VERSION ""

NS_ :

BS_:

BU_: CCU

VAL_TABLE_ Rolling_Counter_0x403 15 "Invalid";
VAL_TABLE_ MHU_SET_TCS_OnOff 0 "OFF (keep sending for 2 seconds)" 1 "ON (keep sending for 2 seconds)" 2 "No action" 3 "Invalid";
VAL_TABLE_ MHU_SET_DrivingModeSwitch 3 "sport mode (should be hold during 1 second)" 2 "normal mode (should be hold during 1 second)" 1 "eco mode (should be hold during 1 second)" 0 "no change request";
VAL_TABLE_ MHU_SET_RegenLevel 3 "No action" 2 "High" 1 "Low" 0 "none";
VAL_TABLE_ MHU_VCU_CreepDisable_stt 0 "No request" 1 "Creep Disable request" 2 "Reserved" 3 "Invalid";
VAL_TABLE_ MHU_HVACTurnON 0 "No request" 1 "ON" 2 "Reserved" 3 "Invalid";
VAL_TABLE_ MHU_ChargeScheduleSet 0 "Disabled" 1 "Enabled" 2 "No Action" 3 "Reserved";
VAL_TABLE_ MHU_ChargingRequest 0 "Reserved" 1 "Request scheduled start charging" 2 "Request stop" 3 "No effect";
VAL_TABLE_ MHU_ValetMode_Activation 0 "Inactive" 1 "Active" 254 "Reserved" 255 "Invalid";
VAL_TABLE_ MHU_CCU_AC_Button 3 "Invalid" 1 "Press" 0 "Release";
VAL_TABLE_ MHU_REC_Button 3 "Invalid" 1 "Press" 0 "Release";
VAL_TABLE_ MHU_SetBlowMode 7 "Invalid" 6 "Reserve" 5 "Reserve" 4 "Foot and window" 3 "Foot" 2 "foot and face" 1 "face" 0 "Inactive";
VAL_TABLE_ MHU_BlowerLevelSetting 9 "level 8" 8 "level 7" 7 "level 6" 6 "level 5" 5 "level 4" 4 "level 3" 3 "level 2" 2 "level 1" 1 "OFF" 0 "Inactive";
VAL_TABLE_ MHU_SetDriverTemp 63 "Invalid" 16 "level 8" 15 "level 7" 14 "level 6" 13 "level 5" 12 "level 4" 11 "level 3" 10 "level 2" 9 "level 1" 8 "level 8" 7 "level 7" 6 "level 6" 5 "level 5" 4 "level 4" 3 "level 3" 2 "level 2" 1 "level 1" 0 "Inactive";
VAL_TABLE_ MHU_ACM_Reserved 3 "Invalid" 1 "Active" 0 "Inactive";
VAL_TABLE_ MHU_FrontDefrostReq_Reserved 3 "Invalid" 1 "Active" 0 "Inactive";
VAL_TABLE_ Rolling_Counter_0x422 15 "Invalid";
VAL_TABLE_ MHU_STAT_DateTimeFormat 3 "Signal invalid" 2 "Reserved" 1 "12H" 0 "24H";
VAL_TABLE_ MHU_DISPLAY_STATUS 0 "OFF" 1 "ON" 2 "Reserved" 3 "Invalid";
VAL_TABLE_ MHU_STAT_Language 31 "Signal invalid" 30 "Reserved" 29 "Reserved" 28 "Reserved" 27 "Reserved" 26 "Reserved" 25 "Reserved" 24 "Reserved" 23 "Reserved" 22 "Reserved" 21 "Reserved" 20 "Reserved" 19 "Reserved" 18 "Reserved" 17 "Reserved" 16 "Reserved" 15 "Reserved" 14 "Reserved" 13 "Reserved" 12 "Reserved" 11 "Reserved" 10 "Reserved" 9 "Reserved" 8 "Reserved" 7 "Reserved" 6 "Cambodia" 5 "Laos" 4 "Indonesian" 3 "Thai" 2 "Malay" 1 "English" 0 "Vietnamese";
VAL_TABLE_ REQ_ConsumerControlAudioVolumeCo 7 "signal invalid" 6 "Reserved" 5 "Reserved" 4 "Reserved" 3 "Reserved" 2 "Level 2" 1 "Level 1" 0 "No Reduction";
VAL_TABLE_ Rolling_Counter_0x432 15 "Invalid";
VAL_TABLE_ MHU_FOTA_State 0 "INIT" 1 "NORMAL" 2 "FOTA FLASHING" 3 "FOTA-SUSPENDED" 4 "FAIL-SAFE-ERROR" 5 "SHUTDOWN" 6 "REMOTE DIAGNOSTICS" 7 "Invalid";
VAL_TABLE_ XGW_FOTA_StateConfirm 0 "INIT" 1 "NORMAL" 2 "FOTA FLASHING" 3 "FOTA-SUSPENDED" 4 "FAIL-SAFE-ERROR" 5 "SHUTDOWN" 6 "REMOTE DIAGNOSTICS" 7 "Invalid";
VAL_TABLE_ IPC_Sec 63 "Invalid";
VAL_TABLE_ IPC_Min 63 "Invalid";
VAL_TABLE_ IPC_Hour 31 "Invalid";
VAL_TABLE_ IPC_Day 31 "Invalid";
VAL_TABLE_ IPC_Month 15 "Invalid";
VAL_TABLE_ IPC_Year 255 "Invalid";
VAL_TABLE_ IPC_SelfCheckStatus 1 "self-check finish" 0 "self-checking";
VAL_TABLE_ Rolling_Counter_0x20C 15 "Invalid";
VAL_TABLE_ IPC_ODO 1048575 "Invalid";
VAL_TABLE_ IPC_TripA 65535 "Invalid";
VAL_TABLE_ IPC_AverageSpeedTripA 4095 "Invalid";
VAL_TABLE_ IPC_AverageConsumptionTripA 1023 "Invalid";
VAL_TABLE_ IPC_ParkBrakeSts 3 "Invalid" 2 "Reserved" 1 "Applied" 0 "Released";
VAL_TABLE_ IPC_VehSpd 32767 "Invalid";
VAL_TABLE_ CCU_TemperatureGearSts 63 "Invalid" 16 "level 8" 15 "level 7" 14 "level 6" 13 "level 5" 12 "level 4" 11 "level 3" 10 "level 2" 9 "level 1" 8 "level 8" 7 "level 7" 6 "level 6" 5 "level 5" 4 "level 4" 3 "level 3" 2 "level 2" 1 "level 1" 0 "Inactive";
VAL_TABLE_ CCU_BlowMode_Sts 7 "Invalid" 6 "Reserve" 4 "Foot and window" 3 "Foot" 2 "Foot and Face" 1 "Face" 0 "OFF";
VAL_TABLE_ CCU_Circulation_Sts 1 "Internal circulation" 0 "Outer circulation";
VAL_TABLE_ CCU_AC_Req 3 "Invalid" 2 "Reserved" 1 "Requset" 0 "No requset";
VAL_TABLE_ CCU_AC_Sts 1 "ON" 0 "OFF";
VAL_TABLE_ CCU_BlowerLevelSts 8 "level 8" 7 "level 7" 6 "level 6" 5 "level 5" 4 "level 4" 3 "level 3" 2 "level 2" 1 "level 1" 0 "OFF";
VAL_TABLE_ CCU_FrontDefrostSts 1 "On" 0 "Off";
VAL_TABLE_ CCU_PTC_Req 3 "Invalid" 2 "Reserved" 1 "Requset" 0 "No requset";
VAL_TABLE_ CCU_PTC_Temperature 1023 "Invaild";
VAL_TABLE_ CCU_CompSpdMEAS_Comp 8191 "Invalid";
VAL_TABLE_ CCU_PollutionSts 1 "ON" 0 "OFF";
VAL_TABLE_ CCU_ExternalTemperature 255 "Invaild";
VAL_TABLE_ CCU_evaporator_Temperature 31 "Invalid";
VAL_TABLE_ CCU_ExternalTemperatureFailSts 1 "invalid" 0 "valid";
VAL_TABLE_ Rolling_Counter_0x85 15 "Invalid";
VAL_TABLE_ ACM_Crash_Sts 3 "Invalid Value" 2 "Invalid Value" 1 "Crash_Detected" 0 "No_Event";
VAL_TABLE_ ACM_Airbag_Deployment_Status 3 "Invalid Value" 2 "Invalid Value" 1 "Airbag_Deployment" 0 "No_Airbag_Deployment";
VAL_TABLE_ ACM_Crash_Intensity 7 "Invalid_Value" 6 "Invalid_Value" 5 "Invalid_Value" 4 "Invalid_Value" 3 "Crash_Intensity_3" 2 "Crash_Intensity_2" 1 "Crash_Intensity_1" 0 "No_Crash";
VAL_TABLE_ ACM_Front_Crash 3 "Invalid Value" 2 "Invalid Value" 1 "Front_Crash_Detected" 0 "No_Event";
VAL_TABLE_ ACM_DriverSide_Crash 3 "Invalid Value" 2 "Invalid Value" 1 "Driverside_Crash_Detected" 0 "No_Event";
VAL_TABLE_ ACM_PassSide_Crash 3 "Invalid Value" 2 "Invalid Value" 1 "PassSide_Crash_Detected" 0 "No_Event";
VAL_TABLE_ ACM_Rear_Crash 3 "Invalid Value" 2 "Invalid Value" 1 "Rear_Crash_Detected" 0 "No_Event";
VAL_TABLE_ ACM_Rollover_Crash 3 "Invalid Value" 2 "Invalid Value" 1 "Rollover_Crash_Detected" 0 "No_Event";
VAL_TABLE_ Rolling_Counter_0x10a 15 "Invalid";
VAL_TABLE_ BCM_LVTop_up 1 "start Top up" 0 "stop Top up";
VAL_TABLE_ Rolling_Counter_0x112 15 "Invalid";
VAL_TABLE_ STAT_Terminal 7 "Signal invalid" 6 "Reserved" 5 "Reserved" 4 "SW update OTA (Not used in VFe34)" 3 "Engine start (eMotor running)" 2 "ON (Driver Present)" 1 "ACC (Park)" 0 "OFF(Comfort Enable)";
VAL_TABLE_ STAT_CL30s_L_Reserved 3 "Signal invalid" 2 "Failure" 1 "ON" 0 "OFF";
VAL_TABLE_ Rolling_Counter_0x342 15 "Invalid";
VAL_TABLE_ ABS_LRWhlSpdRaw 32767 "Invalid";
VAL_TABLE_ ABS_LRWhlSpdRawValid 1 "Valid" 0 "Invalid";
VAL_TABLE_ ABS_RRWhlSpdRaw 32767 "Invalid";
VAL_TABLE_ ABS_RRWhlSpdRawValid 1 "Valid" 0 "Invalid";
VAL_TABLE_ ABS_VehSpd 32767 "Invalid";
VAL_TABLE_ ABS_VehSpdValid 1 "Valid" 0 "Invalid";
VAL_TABLE_ EAC_CompElecCurrV 0 "Valid" 1 "Invalid";
VAL_TABLE_ EAC_CompStat 0 "Normal Operation" 1 "Degraded Operation" 2 "Inoperative" 15 "Invalid";
VAL_TABLE_ EAC_CompElecPwrV 0 "Valid" 1 "Invalid";
VAL_TABLE_ EAC_CompSpdIncrReq 0 "False" 1 "True";
VAL_TABLE_ EAC_CompSpdV 0 "Valid" 1 "Invalid";
VAL_TABLE_ EAC_CompElecPwr 255 "Invaild";
VAL_TABLE_ EAC_CompSpd 16383 "Invaild";
VAL_TABLE_ EAC_CompElecCurr 255 "Invaild";
VAL_TABLE_ EAC_CompFltStat 0 "No Fault" 1 "Under Voltage" 2 "Over Voltage" 3 "Over Temperature" 4 "Input Control" 5 "Current Fault" 6 "Internal Fault" 8 "Motor slip protection" 9 "HVDC input voltage drop protection" 10 "Inside the controller 15V control power supply output undervoltage protection" 11 "Overcurrent frequency limitation and frequency reduction" 15 "Invalid";
VAL_TABLE_ VCU_PTC_RelaySts 1 "close" 0 "open";
VAL_TABLE_ VCU_EACEnbReq 1 "Enable" 0 "Disable";
VAL_TABLE_ VCU_EACAllowedPower 1023 "Invalid";
VAL_TABLE_ VCU_EAC_CompSpdReq 16383 "Invaild";
VAL_TABLE_ VCU_RegenLevel_Feed 3 "invalid" 2 "High" 1 "Low" 0 "none";
VAL_TABLE_ VCU_RBCSts 1 "active" 0 "incative";
VAL_TABLE_ VCU_RDCSts 1 "active" 0 "incative";
VAL_TABLE_ VCU_Veh_ERR 1 "Error" 0 "Normal";
VAL_TABLE_ VCU_DrvSys_ERR 1 "Error" 0 "Normal";
VAL_TABLE_ VCU_PackSys_ERR 1 "Error" 0 "Normal";
VAL_TABLE_ VCU_TBOX_Veh_STS_Reserved 3 "Other" 2 "Off" 1 "Start" 0 "Invalid";
VAL_TABLE_ VCU_VehChg_STS 3 "Charge fault" 2 "Charging complete" 1 "Charging in progress" 0 "Charging not in progress";
VAL_TABLE_ VCU_BatterVoltage_Reserved 255 "Invalid";
VAL_TABLE_ VCU_BatteryVoltErr_Reserved 1 "warning" 0 "no warning";
VAL_TABLE_ VCU_MotorCoolingCircuitErr_Reserved 1 "Error" 0 "Normal";
VAL_TABLE_ VCU_PackCoolingCircuitErr_Reserved 1 "Error" 0 "Normal";
VAL_TABLE_ VCU_VehicleHVStatus 3 "Reserved" 2 "ReadyToDrive" 1 "HV On" 0 "Not ready";
VAL_TABLE_ VCU_InstantPowerConsump 1023 "Invalid";
VAL_TABLE_ VCU_AveragePowerConsump 1023 "Invalid";
VAL_TABLE_ VCU_BrakePedalSts 3 "Invalid" 2 "Reserved" 1 "pressed" 0 "Not pressed";
VAL_TABLE_ VCU_IMMO_Sts 2 "failed " 1 "pass " 0 "init";
VAL_TABLE_ VCU_DCDCAllowedPower 511 "Invalid";
VAL_TABLE_ VCU_Shift_ERR 1 "Error" 0 "Normal";
VAL_TABLE_ VCU_VehicleDischargePower 127 "Invalid";
VAL_TABLE_ VCU_VehicleChargePower 127 "Invalid";
VAL_TABLE_ Rolling_Counter_0x215 15 "Invalid";
VAL_TABLE_ BMS_SOE 255 "Invalid";
VAL_TABLE_ BMS_HWCrash_Sts 1 "Crash " 0 "No Crash";
VAL_TABLE_ BMS_HVIL_STS 2 "short to ground" 1 "Open & short to battery" 0 "Closed";
VAL_TABLE_ BMS_IGN_Sts 1 "ON " 0 "OFF";
VAL_TABLE_ BMS_Sys_STS 8 "Invalid" 7 "Failure, unable to operate" 6 "BCU Sleep mode" 5 "Successful Power Down" 4 "Power Down process" 3 "Successful Power Down of HV" 2 "Successful High Voltage Power Up" 1 "Self-check passes, can be high-voltage" 0 "Initialization of power on, self-checking";
VAL_TABLE_ BMS_HVOnOff_STS 3 "Fail to HV on " 2 "HV On " 1 "Precharge " 0 "HV Off";
VAL_TABLE_ BMS_Balance_STS 1 "active " 0 "Inactive";
VAL_TABLE_ BMS_SocActual_EST 1023 "Invalid";
VAL_TABLE_ BMS_BatBalance_ERR 1 "normal " 0 "Error";
VAL_TABLE_ BMS_ISU_Status 3 "Level3(<100 Ohms/V)" 2 "Level2(<200 Ohms/V)" 1 "Level1 <500 Ohms/V ~ >200 Ohms/V" 0 "Normal (> 500 Ohms/V)";
VAL_TABLE_ BMS_ERR_LEV 7 "Battery locked -Reserved" 6 "Fault, needs Shutdown and Wakeup" 5 "Emergency off condition" 4 "Delayed power down with FTTI" 3 "Power down without FTTI" 2 "Limp Home" 1 " Warning (any warning in system)" 0 "No error";
VAL_TABLE_ BMS_SOH 255 "Invalid";
VAL_TABLE_ BMS_HV_Sts 4 "AC Charge" 3 "Super Fast Charge" 2 "HV ON" 1 "Precharge" 0 "HV Off";
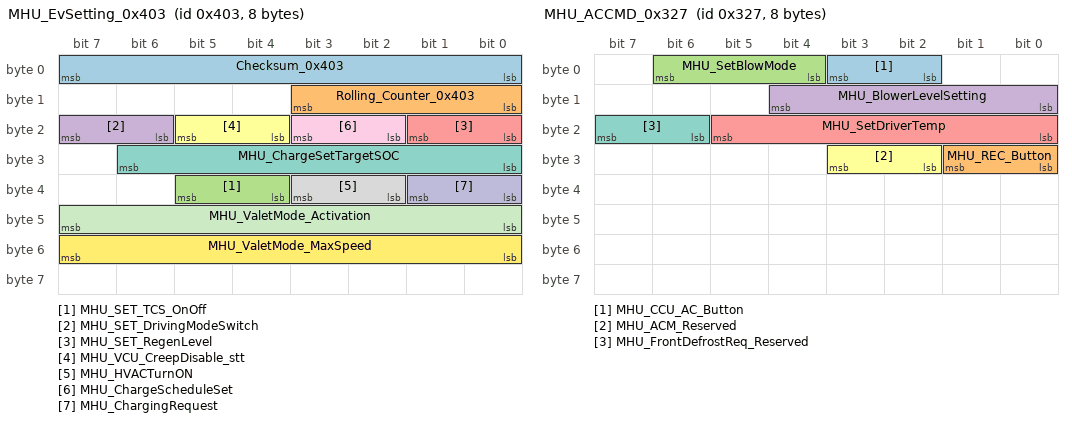
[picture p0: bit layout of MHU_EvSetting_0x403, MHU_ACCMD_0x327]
BO_ 1027 MHU_EvSetting_0x403: 8 Vector__XXX
 SG_ Checksum_0x403 : 7|8@0+ (1,0) [0|255] "" Vector__XXX
 SG_ Rolling_Counter_0x403 : 11|4@0+ (1,0) [0|15] "" Vector__XXX
 SG_ MHU_SET_TCS_OnOff : 37|2@0+ (1,0) [0|3] "" Vector__XXX
 SG_ MHU_SET_DrivingModeSwitch : 23|2@0+ (1,0) [0|3] "" Vector__XXX
 SG_ MHU_SET_RegenLevel : 17|2@0+ (1,0) [0|3] "" Vector__XXX
 SG_ MHU_VCU_CreepDisable_stt : 21|2@0+ (1,0) [0|3] "" Vector__XXX
 SG_ MHU_ChargeSetTargetSOC : 30|7@0+ (1,0) [10|100] "Percentage" Vector__XXX
 SG_ MHU_HVACTurnON : 35|2@0+ (1,0) [0|3] "" CCU
 SG_ MHU_ChargeScheduleSet : 19|2@0+ (1,0) [0|3] "" Vector__XXX
 SG_ MHU_ChargingRequest : 33|2@0+ (1,0) [0|3] "" Vector__XXX
 SG_ MHU_ValetMode_Activation : 47|8@0+ (1,0) [0|254] "" Vector__XXX
 SG_ MHU_ValetMode_MaxSpeed : 55|8@0+ (1,0) [0|254] "kph" Vector__XXX
BO_ 807 MHU_ACCMD_0x327: 8 Vector__XXX
 SG_ MHU_CCU_AC_Button : 3|2@0+ (1,0) [0|3] "" CCU
 SG_ MHU_REC_Button : 25|2@0+ (1,0) [0|3] "" CCU
 SG_ MHU_SetBlowMode : 6|3@0+ (1,0) [0|7] "" CCU
 SG_ MHU_BlowerLevelSetting : 12|5@0+ (1,0) [0|9] "" CCU
 SG_ MHU_SetDriverTemp : 21|6@0+ (1,0) [0|63] "" CCU
 SG_ MHU_ACM_Reserved : 27|2@0+ (1,0) [0|3] "" CCU
 SG_ MHU_FrontDefrostReq_Reserved : 23|2@0+ (1,0) [0|3] "" CCU
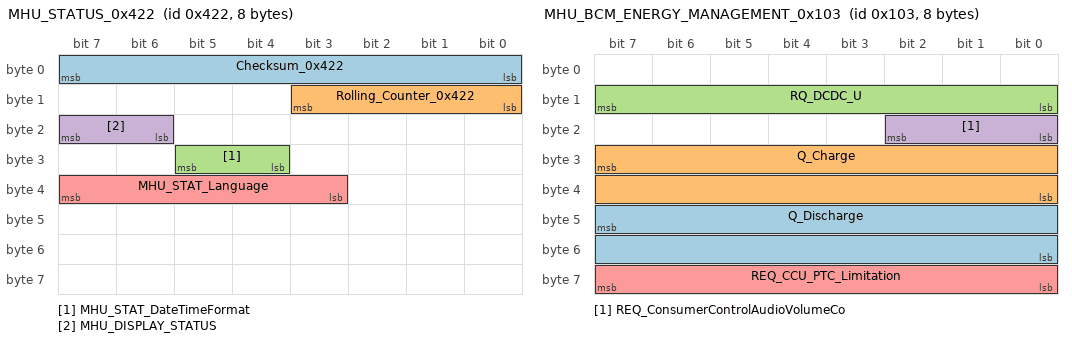
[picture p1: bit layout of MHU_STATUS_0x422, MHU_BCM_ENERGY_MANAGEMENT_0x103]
BO_ 1058 MHU_STATUS_0x422: 8 Vector__XXX
 SG_ Checksum_0x422 : 7|8@0+ (1,0) [0|255] "" Vector__XXX
 SG_ Rolling_Counter_0x422 : 11|4@0+ (1,0) [0|15] "" Vector__XXX
 SG_ MHU_STAT_DateTimeFormat : 29|2@0+ (1,0) [0|3] "" Vector__XXX
 SG_ MHU_DISPLAY_STATUS : 23|2@0+ (1,0) [0|3] "" CCU
 SG_ MHU_STAT_Language : 39|5@0+ (1,0) [0|31] "" Vector__XXX
BO_ 259 MHU_BCM_ENERGY_MANAGEMENT_0x103: 8 Vector__XXX
 SG_ Q_Discharge : 47|16@0+ (0.125,0) [0|8191.75] "Ah" CCU
 SG_ Q_Charge : 31|16@0+ (0.125,0) [0|8191.75] "Ah" CCU
 SG_ RQ_DCDC_U : 15|8@0+ (0.1,0) [0|25.2] "Vol" CCU
 SG_ REQ_ConsumerControlAudioVolumeCo : 18|3@0+ (1,0) [0|7] "" CCU
 SG_ REQ_CCU_PTC_Limitation : 63|8@0+ (1,0) [0|100] "percent" CCU
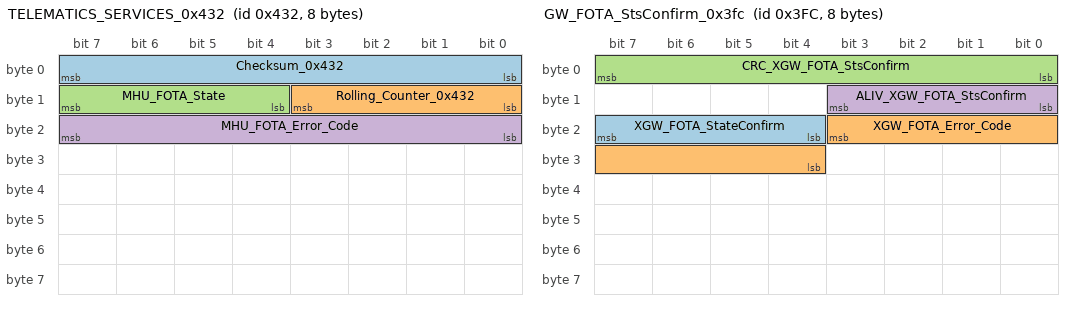
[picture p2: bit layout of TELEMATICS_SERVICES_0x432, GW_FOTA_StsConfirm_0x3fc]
BO_ 1074 TELEMATICS_SERVICES_0x432: 8 Vector__XXX
 SG_ Checksum_0x432 : 7|8@0+ (1,0) [0|255] "" CCU
 SG_ Rolling_Counter_0x432 : 11|4@0+ (1,0) [0|14] "" CCU
 SG_ MHU_FOTA_State : 15|4@0+ (1,0) [0|14] "" CCU
 SG_ MHU_FOTA_Error_Code : 23|8@0+ (1,0) [0|255] "" CCU
BO_ 1020 GW_FOTA_StsConfirm_0x3fc: 8 Vector__XXX
 SG_ XGW_FOTA_StateConfirm : 23|4@0+ (1,0) [0|14] "" CCU
 SG_ XGW_FOTA_Error_Code : 19|8@0+ (1,0) [0|255] "" Vector__XXX
 SG_ CRC_XGW_FOTA_StsConfirm : 7|8@0+ (1,0) [0|255] "" Vector__XXX
 SG_ ALIV_XGW_FOTA_StsConfirm : 11|4@0+ (1,0) [0|14] "" Vector__XXX
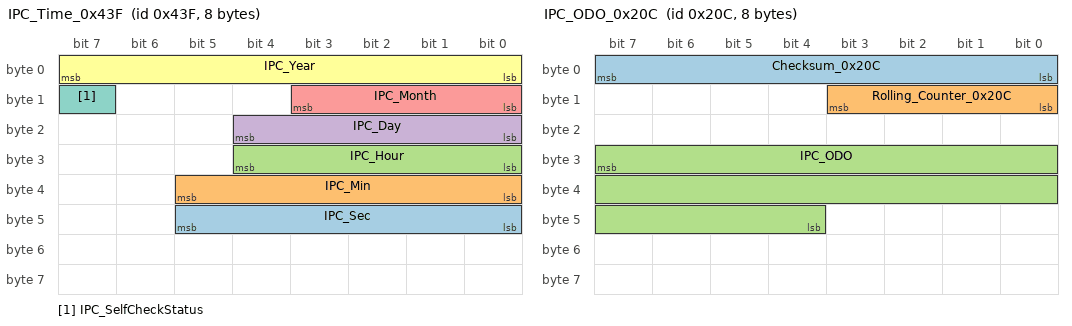
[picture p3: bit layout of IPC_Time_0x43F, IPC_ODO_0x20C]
BO_ 1087 IPC_Time_0x43F: 8 Vector__XXX
 SG_ IPC_Sec : 45|6@0+ (1,0) [0|59] "second" CCU
 SG_ IPC_Min : 37|6@0+ (1,0) [0|59] "min" CCU
 SG_ IPC_Hour : 28|5@0+ (1,0) [0|23] "hour" CCU
 SG_ IPC_Day : 20|5@0+ (1,0) [1|31] "" CCU
 SG_ IPC_Month : 11|4@0+ (1,0) [1|12] "" CCU
 SG_ IPC_Year : 7|8@0+ (1,2000) [2000|2255] "" CCU
 SG_ IPC_SelfCheckStatus : 15|1@0+ (1,0) [0|1] "" CCU
BO_ 524 IPC_ODO_0x20C: 8 Vector__XXX
 SG_ Checksum_0x20C : 7|8@0+ (1,0) [0|255] "" Vector__XXX
 SG_ Rolling_Counter_0x20C : 11|4@0+ (1,0) [0|15] "" Vector__XXX
 SG_ IPC_ODO : 31|20@0+ (1,0) [0|999999] "km" CCU
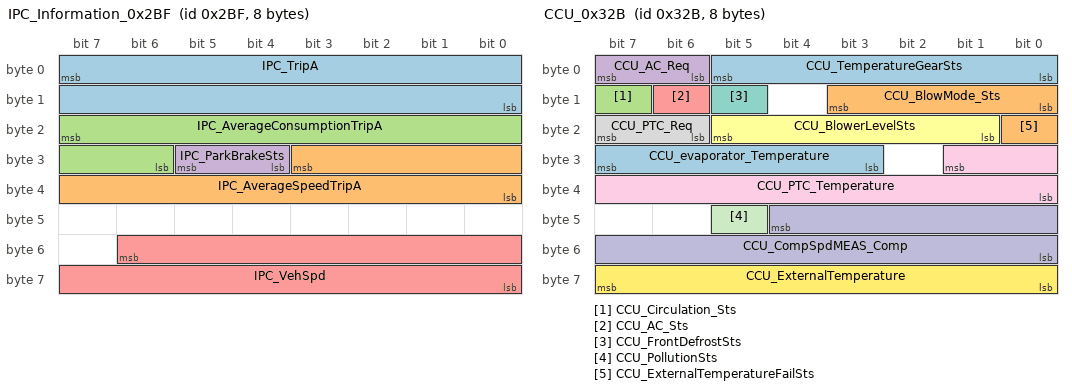
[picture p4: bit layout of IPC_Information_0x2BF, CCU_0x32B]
BO_ 703 IPC_Information_0x2BF: 8 Vector__XXX
 SG_ IPC_TripA : 7|16@0+ (0.1,0) [0|999.9] "km" Vector__XXX
 SG_ IPC_AverageSpeedTripA : 27|12@0+ (0.0625,0) [0|250] "km/h" Vector__XXX
 SG_ IPC_AverageConsumptionTripA : 23|10@0+ (0.1,0) [0|100] "kwh/100km" Vector__XXX
 SG_ IPC_ParkBrakeSts : 29|2@0+ (1,0) [0|3] "" Vector__XXX
 SG_ IPC_VehSpd : 54|15@0+ (0.01,0) [0|327.66] "kph" CCU
BO_ 811 CCU_0x32B: 8 CCU
 SG_ CCU_TemperatureGearSts : 5|6@0+ (1,0) [0|63] "" Vector__XXX
 SG_ CCU_BlowMode_Sts : 11|4@0+ (1,0) [0|15] "" Vector__XXX
 SG_ CCU_Circulation_Sts : 15|1@0+ (1,0) [0|1] "" Vector__XXX
 SG_ CCU_AC_Req : 7|2@0+ (1,0) [0|3] "" Vector__XXX
 SG_ CCU_AC_Sts : 14|1@0+ (1,0) [0|1] "" Vector__XXX
 SG_ CCU_BlowerLevelSts : 21|5@0+ (1,0) [0|9] "" Vector__XXX
 SG_ CCU_FrontDefrostSts : 13|1@0+ (1,0) [0|1] "" Vector__XXX
 SG_ CCU_PTC_Req : 23|2@0+ (1,0) [0|3] "" Vector__XXX
 SG_ CCU_PTC_Temperature : 25|10@0+ (0.1,0) [0|100] "°C" Vector__XXX
 SG_ CCU_CompSpdMEAS_Comp : 44|13@0+ (1,0) [0|8191] "rpm" Vector__XXX
 SG_ CCU_PollutionSts : 45|1@0+ (1,0) [0|1] "" Vector__XXX
 SG_ CCU_ExternalTemperature : 63|8@0+ (0.5,-40) [-40|87] "°C" Vector__XXX
 SG_ CCU_evaporator_Temperature : 31|5@0+ (1,-10) [-10|20] "°C" Vector__XXX
 SG_ CCU_ExternalTemperatureFailSts : 16|1@0+ (1,0) [0|1] "" Vector__XXX
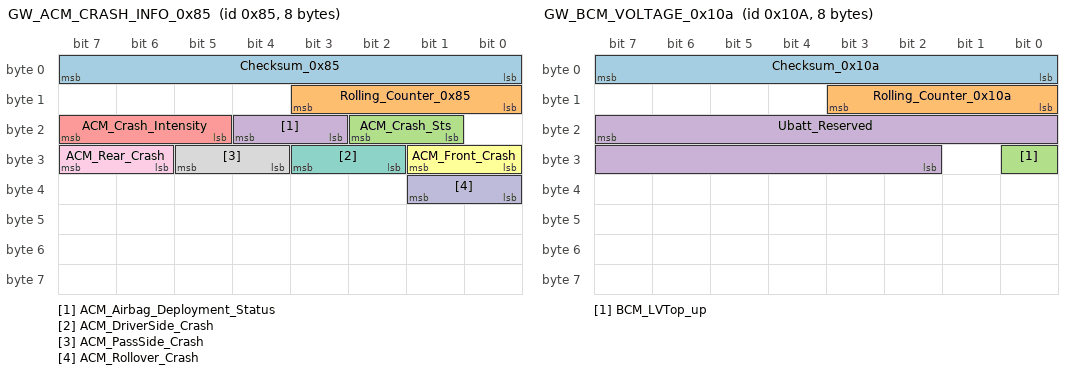
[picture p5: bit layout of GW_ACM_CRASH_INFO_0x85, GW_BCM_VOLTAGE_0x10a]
BO_ 133 GW_ACM_CRASH_INFO_0x85: 8 Vector__XXX
 SG_ Checksum_0x85 : 7|8@0+ (1,0) [0|255] "" CCU
 SG_ Rolling_Counter_0x85 : 11|4@0+ (1,0) [0|15] "" CCU
 SG_ ACM_Crash_Sts : 18|2@0+ (1,0) [0|3] "" CCU
 SG_ ACM_Airbag_Deployment_Status : 20|2@0+ (1,0) [0|3] "" Vector__XXX
 SG_ ACM_Crash_Intensity : 23|3@0+ (1,0) [0|7] "" Vector__XXX
 SG_ ACM_Front_Crash : 25|2@0+ (1,0) [0|3] "" Vector__XXX
 SG_ ACM_DriverSide_Crash : 27|2@0+ (1,0) [0|3] "" Vector__XXX
 SG_ ACM_PassSide_Crash : 29|2@0+ (1,0) [0|3] "" Vector__XXX
 SG_ ACM_Rear_Crash : 31|2@0+ (1,0) [0|3] "" Vector__XXX
 SG_ ACM_Rollover_Crash : 33|2@0+ (1,0) [0|3] "" Vector__XXX
BO_ 266 GW_BCM_VOLTAGE_0x10a: 8 Vector__XXX
 SG_ Checksum_0x10a : 7|8@0+ (1,0) [0|255] "" CCU
 SG_ Rolling_Counter_0x10a : 11|4@0+ (1,0) [0|15] "" CCU
 SG_ BCM_LVTop_up : 24|1@0+ (1,0) [0|1] "" Vector__XXX
 SG_ Ubatt_Reserved : 23|14@0+ (0.001,3) [3|18] "V" CCU
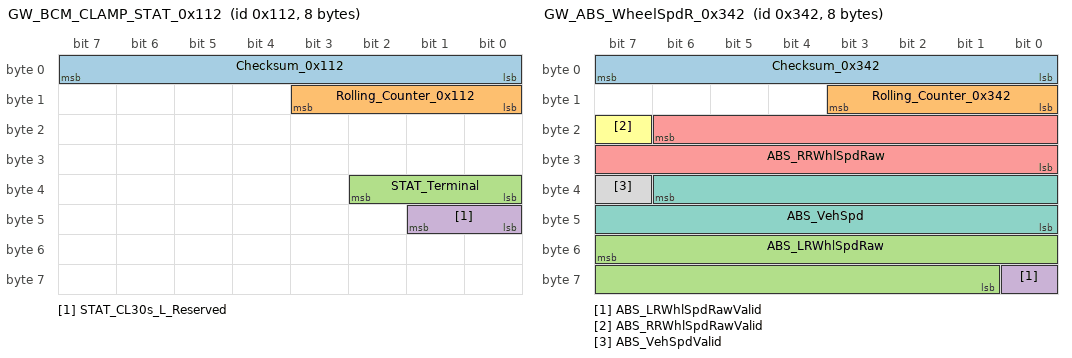
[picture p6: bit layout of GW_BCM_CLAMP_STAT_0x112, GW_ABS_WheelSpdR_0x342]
BO_ 274 GW_BCM_CLAMP_STAT_0x112: 8 Vector__XXX
 SG_ Checksum_0x112 : 7|8@0+ (1,0) [0|255] "" CCU
 SG_ Rolling_Counter_0x112 : 11|4@0+ (1,0) [0|15] "" CCU
 SG_ STAT_Terminal : 34|3@0+ (1,0) [0|7] "Bit" CCU
 SG_ STAT_CL30s_L_Reserved : 41|2@0+ (1,0) [0|3] "Bit" Vector__XXX
BO_ 834 GW_ABS_WheelSpdR_0x342: 8 Vector__XXX
 SG_ Checksum_0x342 : 7|8@0+ (1,0) [0|255] "" CCU
 SG_ Rolling_Counter_0x342 : 11|4@0+ (1,0) [0|15] "" CCU
 SG_ ABS_LRWhlSpdRaw : 55|15@0+ (0.01,0) [0|327.66] "kph" Vector__XXX
 SG_ ABS_LRWhlSpdRawValid : 56|1@0+ (1,0) [0|1] "" Vector__XXX
 SG_ ABS_RRWhlSpdRaw : 22|15@0+ (0.01,0) [0|327.66] "kph" Vector__XXX
 SG_ ABS_RRWhlSpdRawValid : 23|1@0+ (1,0) [0|1] "" Vector__XXX
 SG_ ABS_VehSpd : 38|15@0+ (0.01,0) [0|327.66] "kph" CCU
 SG_ ABS_VehSpdValid : 39|1@0+ (1,0) [0|1] "" CCU
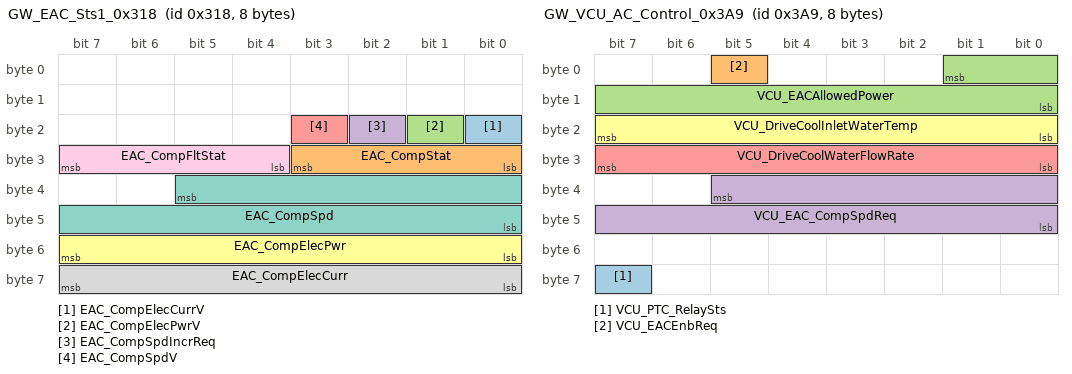
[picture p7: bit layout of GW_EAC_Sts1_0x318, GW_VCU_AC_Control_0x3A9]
BO_ 792 GW_EAC_Sts1_0x318: 8 Vector__XXX
 SG_ EAC_CompElecCurrV : 16|1@0+ (1,0) [0|1] "" Vector__XXX
 SG_ EAC_CompStat : 27|4@0+ (1,0) [0|15] "" CCU
 SG_ EAC_CompElecPwrV : 17|1@0+ (1,0) [0|1] "" Vector__XXX
 SG_ EAC_CompSpdIncrReq : 18|1@0+ (1,0) [0|1] "" Vector__XXX
 SG_ EAC_CompSpdV : 19|1@0+ (1,0) [0|1] "" CCU
 SG_ EAC_CompElecPwr : 55|8@0+ (40,0) [0|10200] "W" CCU
 SG_ EAC_CompSpd : 37|14@0+ (1,0) [0|16383] "rpm" CCU
 SG_ EAC_CompElecCurr : 63|8@0+ (0.2,0) [0|51] "A" Vector__XXX
 SG_ EAC_CompFltStat : 31|4@0+ (1,0) [0|15] "" CCU
BO_ 937 GW_VCU_AC_Control_0x3A9: 8 Vector__XXX
 SG_ VCU_PTC_RelaySts : 63|1@0+ (1,0) [0|1] "" CCU
 SG_ VCU_EACEnbReq : 5|1@0+ (1,0) [0|1] "" Vector__XXX
 SG_ VCU_EACAllowedPower : 1|10@0+ (0.1,0) [0|100] "KW" Vector__XXX
 SG_ VCU_EAC_CompSpdReq : 37|14@0+ (1,0) [0|16383] "rpm" Vector__XXX
 SG_ VCU_DriveCoolWaterFlowRate : 31|8@0+ (0.1,0) [0|25.4] "L/min" Vector__XXX
 SG_ VCU_DriveCoolInletWaterTemp : 23|8@0+ (1,-40) [-40|215] "degree" Vector__XXX
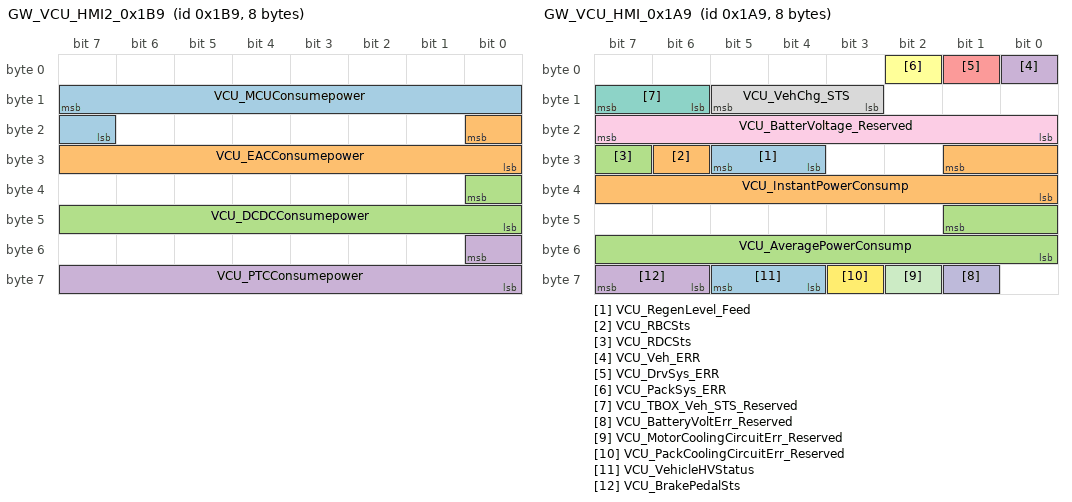
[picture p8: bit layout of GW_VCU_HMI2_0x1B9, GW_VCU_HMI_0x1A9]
BO_ 441 GW_VCU_HMI2_0x1B9: 8 Vector__XXX
 SG_ VCU_MCUConsumepower : 15|9@0+ (0.1,0) [0|50] "kw/h" Vector__XXX
 SG_ VCU_EACConsumepower : 16|9@0+ (0.1,0) [0|50] "kw/h" Vector__XXX
 SG_ VCU_DCDCConsumepower : 32|9@0+ (0.1,0) [0|50] "kw/h" Vector__XXX
 SG_ VCU_PTCConsumepower : 48|9@0+ (0.1,0) [0|50] "kw/h" Vector__XXX
BO_ 425 GW_VCU_HMI_0x1A9: 8 Vector__XXX
 SG_ VCU_RegenLevel_Feed : 29|2@0+ (1,0) [0|3] "" Vector__XXX
 SG_ VCU_RBCSts : 30|1@0+ (1,0) [0|1] "" Vector__XXX
 SG_ VCU_RDCSts : 31|1@0+ (1,0) [0|1] "" Vector__XXX
 SG_ VCU_Veh_ERR : 0|1@0+ (1,0) [0|1] "" Vector__XXX
 SG_ VCU_DrvSys_ERR : 1|1@0+ (1,0) [0|1] "" Vector__XXX
 SG_ VCU_PackSys_ERR : 2|1@0+ (1,0) [0|1] "" Vector__XXX
 SG_ VCU_TBOX_Veh_STS_Reserved : 15|2@0+ (1,0) [0|3] "" Vector__XXX
 SG_ VCU_VehChg_STS : 13|3@0+ (1,0) [0|7] "" Vector__XXX
 SG_ VCU_BatterVoltage_Reserved : 23|8@0+ (0.07,0) [0|17.85] "V" Vector__XXX
 SG_ VCU_BatteryVoltErr_Reserved : 57|1@0+ (1,0) [0|1] "" Vector__XXX
 SG_ VCU_MotorCoolingCircuitErr_Reserved : 58|1@0+ (1,0) [0|1] "" Vector__XXX
 SG_ VCU_PackCoolingCircuitErr_Reserved : 59|1@0+ (1,0) [0|1] "" Vector__XXX
 SG_ VCU_VehicleHVStatus : 61|2@0+ (1,0) [0|3] "" CCU
 SG_ VCU_InstantPowerConsump : 25|10@0+ (0.1,0) [0|100] "kwh/100km" Vector__XXX
 SG_ VCU_AveragePowerConsump : 41|10@0+ (0.1,0) [0|100] "kwh/100km" Vector__XXX
 SG_ VCU_BrakePedalSts : 63|2@0+ (1,0) [0|3] "" Vector__XXX
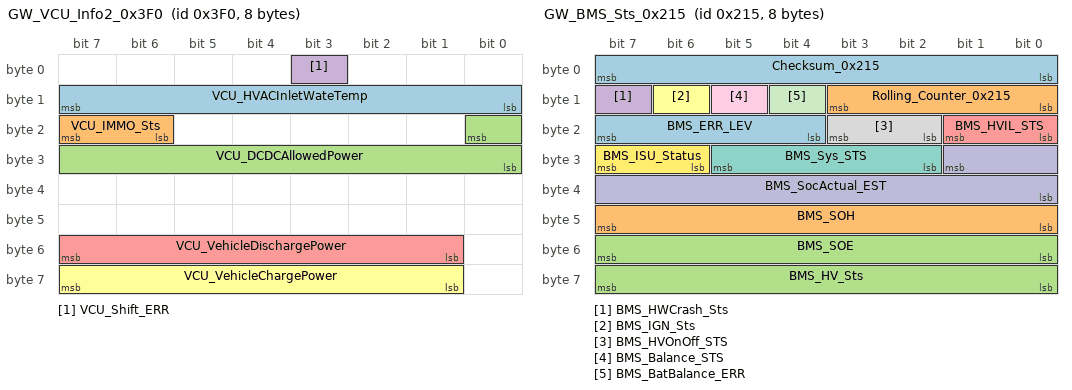
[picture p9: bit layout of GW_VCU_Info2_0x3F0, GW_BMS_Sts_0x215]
BO_ 1008 GW_VCU_Info2_0x3F0: 8 Vector__XXX
 SG_ VCU_HVACInletWateTemp : 15|8@0+ (1,-40) [-40|215] "degree" CCU
 SG_ VCU_IMMO_Sts : 23|2@0+ (1,0) [0|2] "" Vector__XXX
 SG_ VCU_DCDCAllowedPower : 16|9@0+ (0.1,0) [0|50] "KW" Vector__XXX
 SG_ VCU_Shift_ERR : 3|1@0+ (1,0) [0|1] "" Vector__XXX
 SG_ VCU_VehicleDischargePower : 55|7@0+ (1,0) [0|100] "%" Vector__XXX
 SG_ VCU_VehicleChargePower : 63|7@0+ (1,0) [0|100] "%" Vector__XXX
BO_ 533 GW_BMS_Sts_0x215: 8 Vector__XXX
 SG_ Checksum_0x215 : 7|8@0+ (1,0) [0|255] "" CCU
 SG_ Rolling_Counter_0x215 : 11|4@0+ (1,0) [0|15] "" CCU
 SG_ BMS_SOE : 55|8@0+ (0.5,0) [0|100] "%" Vector__XXX
 SG_ BMS_HWCrash_Sts : 15|1@0+ (1,0) [0|1] "" Vector__XXX
 SG_ BMS_HVIL_STS : 17|2@0+ (1,0) [0|3] "" Vector__XXX
 SG_ BMS_IGN_Sts : 14|1@0+ (1,0) [0|1] "" Vector__XXX
 SG_ BMS_Sys_STS : 29|4@0+ (1,0) [0|15] "" Vector__XXX
 SG_ BMS_HVOnOff_STS : 19|2@0+ (1,0) [0|3] "" CCU
 SG_ BMS_Balance_STS : 13|1@0+ (1,0) [0|1] "" Vector__XXX
 SG_ BMS_SocActual_EST : 25|10@0+ (0.1,0) [0|100] "percent" Vector__XXX
 SG_ BMS_BatBalance_ERR : 12|1@0+ (1,0) [0|1] "" Vector__XXX
 SG_ BMS_ISU_Status : 31|2@0+ (1,0) [0|3] "" Vector__XXX
 SG_ BMS_ERR_LEV : 23|4@0+ (1,0) [0|15] "" Vector__XXX
 SG_ BMS_SOH : 47|8@0+ (0.5,0) [0|100] "%" Vector__XXX
 SG_ BMS_HV_Sts : 63|8@0+ (1,0) [0|255] "" Vector__XXX
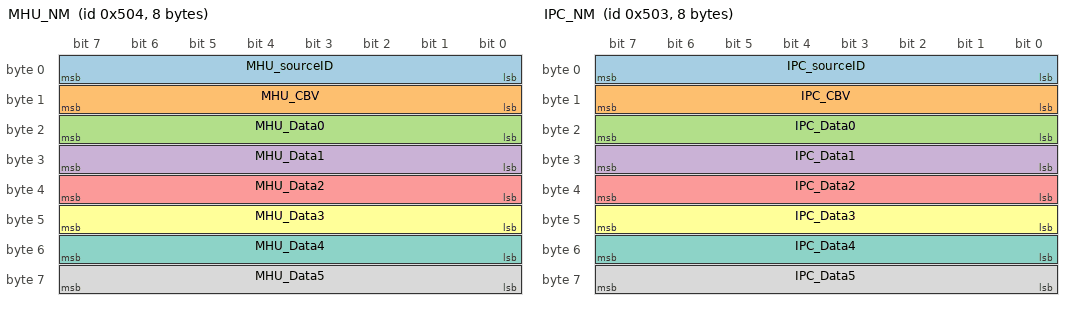
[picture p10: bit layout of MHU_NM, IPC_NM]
BO_ 1284 MHU_NM: 8 Vector__XXX
 SG_ MHU_sourceID : 7|8@0+ (1,0) [0|255] "" CCU
 SG_ MHU_CBV : 15|8@0+ (1,0) [0|255] "" CCU
 SG_ MHU_Data0 : 23|8@0+ (1,0) [0|255] "" CCU
 SG_ MHU_Data1 : 31|8@0+ (1,0) [0|255] "" CCU
 SG_ MHU_Data2 : 39|8@0+ (1,0) [0|255] "" CCU
 SG_ MHU_Data3 : 47|8@0+ (1,0) [0|255] "" CCU
 SG_ MHU_Data4 : 55|8@0+ (1,0) [0|255] "" CCU
 SG_ MHU_Data5 : 63|8@0+ (1,0) [0|255] "" CCU
BO_ 1283 IPC_NM: 8 Vector__XXX
 SG_ IPC_sourceID : 7|8@0+ (1,0) [0|255] "" CCU
 SG_ IPC_CBV : 15|8@0+ (1,0) [0|255] "" CCU
 SG_ IPC_Data0 : 23|8@0+ (1,0) [0|255] "" CCU
 SG_ IPC_Data1 : 31|8@0+ (1,0) [0|255] "" CCU
 SG_ IPC_Data2 : 39|8@0+ (1,0) [0|255] "" CCU
 SG_ IPC_Data3 : 47|8@0+ (1,0) [0|255] "" CCU
 SG_ IPC_Data4 : 55|8@0+ (1,0) [0|255] "" CCU
 SG_ IPC_Data5 : 63|8@0+ (1,0) [0|255] "" CCU
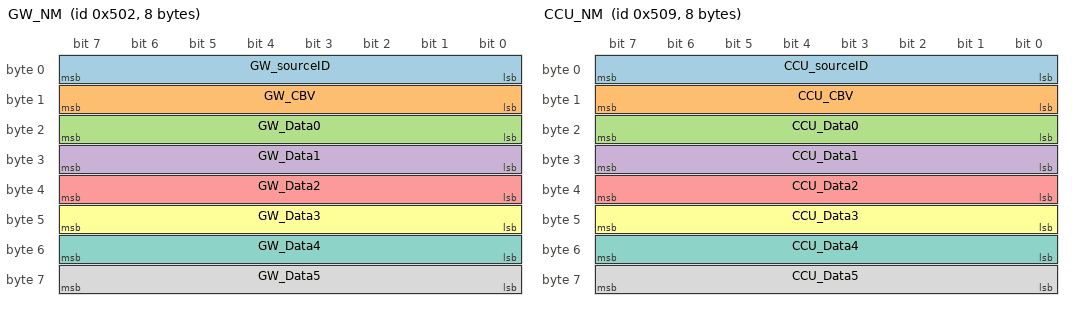
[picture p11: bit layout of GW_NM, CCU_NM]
BO_ 1282 GW_NM: 8 Vector__XXX
 SG_ GW_sourceID : 7|8@0+ (1,0) [0|255] "" CCU
 SG_ GW_CBV : 15|8@0+ (1,0) [0|255] "" CCU
 SG_ GW_Data0 : 23|8@0+ (1,0) [0|255] "" CCU
 SG_ GW_Data1 : 31|8@0+ (1,0) [0|255] "" CCU
 SG_ GW_Data2 : 39|8@0+ (1,0) [0|255] "" CCU
 SG_ GW_Data3 : 47|8@0+ (1,0) [0|255] "" CCU
 SG_ GW_Data4 : 55|8@0+ (1,0) [0|255] "" CCU
 SG_ GW_Data5 : 63|8@0+ (1,0) [0|255] "" CCU
BO_ 1289 CCU_NM: 8 CCU
 SG_ CCU_sourceID : 7|8@0+ (1,0) [0|255] "" Vector__XXX
 SG_ CCU_CBV : 15|8@0+ (1,0) [0|255] "" Vector__XXX
 SG_ CCU_Data0 : 23|8@0+ (1,0) [0|255] "" Vector__XXX
 SG_ CCU_Data1 : 31|8@0+ (1,0) [0|255] "" Vector__XXX
 SG_ CCU_Data2 : 39|8@0+ (1,0) [0|255] "" Vector__XXX
 SG_ CCU_Data3 : 47|8@0+ (1,0) [0|255] "" Vector__XXX
 SG_ CCU_Data4 : 55|8@0+ (1,0) [0|255] "" Vector__XXX
 SG_ CCU_Data5 : 63|8@0+ (1,0) [0|255] "" Vector__XXX
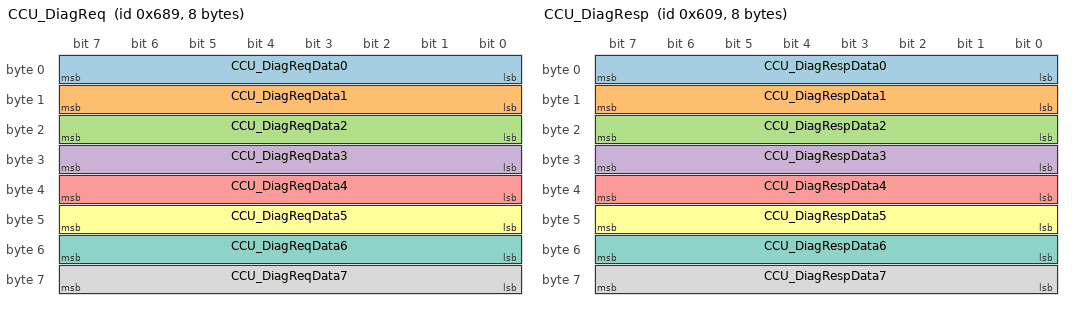
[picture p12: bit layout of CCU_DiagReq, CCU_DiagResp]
BO_ 1673 CCU_DiagReq: 8 Vector__XXX
 SG_ CCU_DiagReqData0 : 7|8@0+ (1,0) [0|255] "" CCU
 SG_ CCU_DiagReqData1 : 15|8@0+ (1,0) [0|255] "" CCU
 SG_ CCU_DiagReqData2 : 23|8@0+ (1,0) [0|255] "" CCU
 SG_ CCU_DiagReqData3 : 31|8@0+ (1,0) [0|255] "" CCU
 SG_ CCU_DiagReqData4 : 39|8@0+ (1,0) [0|255] "" CCU
 SG_ CCU_DiagReqData5 : 47|8@0+ (1,0) [0|255] "" CCU
 SG_ CCU_DiagReqData6 : 55|8@0+ (1,0) [0|255] "" CCU
 SG_ CCU_DiagReqData7 : 63|8@0+ (1,0) [0|255] "" CCU
BO_ 1545 CCU_DiagResp: 8 CCU
 SG_ CCU_DiagRespData0 : 7|8@0+ (1,0) [0|255] "" Vector__XXX
 SG_ CCU_DiagRespData1 : 15|8@0+ (1,0) [0|255] "" Vector__XXX
 SG_ CCU_DiagRespData2 : 23|8@0+ (1,0) [0|255] "" Vector__XXX
 SG_ CCU_DiagRespData3 : 31|8@0+ (1,0) [0|255] "" Vector__XXX
 SG_ CCU_DiagRespData4 : 39|8@0+ (1,0) [0|255] "" Vector__XXX
 SG_ CCU_DiagRespData5 : 47|8@0+ (1,0) [0|255] "" Vector__XXX
 SG_ CCU_DiagRespData6 : 55|8@0+ (1,0) [0|255] "" Vector__XXX
 SG_ CCU_DiagRespData7 : 63|8@0+ (1,0) [0|255] "" Vector__XXX
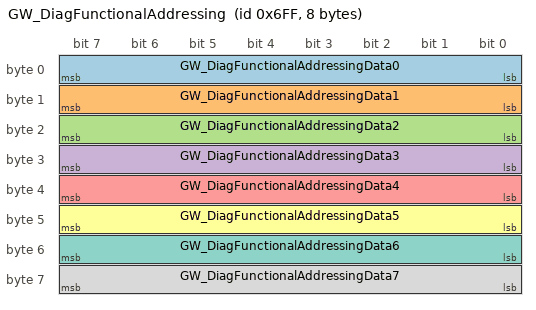
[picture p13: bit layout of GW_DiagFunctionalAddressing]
BO_ 1791 GW_DiagFunctionalAddressing: 8 Vector__XXX
 SG_ GW_DiagFunctionalAddressingData0 : 7|8@0+ (1,0) [0|255] "" CCU
 SG_ GW_DiagFunctionalAddressingData1 : 15|8@0+ (1,0) [0|255] "" CCU
 SG_ GW_DiagFunctionalAddressingData2 : 23|8@0+ (1,0) [0|255] "" CCU
 SG_ GW_DiagFunctionalAddressingData3 : 31|8@0+ (1,0) [0|255] "" CCU
 SG_ GW_DiagFunctionalAddressingData4 : 39|8@0+ (1,0) [0|255] "" CCU
 SG_ GW_DiagFunctionalAddressingData5 : 47|8@0+ (1,0) [0|255] "" CCU
 SG_ GW_DiagFunctionalAddressingData6 : 55|8@0+ (1,0) [0|255] "" CCU
 SG_ GW_DiagFunctionalAddressingData7 : 63|8@0+ (1,0) [0|255] "" CCU
CM_ SG_ 1027 Checksum_0x403 "Checksum";
CM_ SG_ 1027 Rolling_Counter_0x403 "Rolling_Counter";
CM_ SG_ 1027 MHU_SET_TCS_OnOff "Change TCS mode ON/OFF";
CM_ SG_ 1027 MHU_SET_DrivingModeSwitch "Change vehicle driving mode";
CM_ SG_ 1027 MHU_SET_RegenLevel "Set power regenerative level";
CM_ SG_ 1027 MHU_VCU_CreepDisable_stt "Request for VCU to disable creep function";
CM_ SG_ 1027 MHU_ChargeSetTargetSOC "Request for VCU to set target HV SOC";
CM_ SG_ 1027 MHU_HVACTurnON "Turning ON HVAC remotely";
CM_ SG_ 1027 MHU_ChargeScheduleSet "Request for VCU to enable/disable Charging Scheduling";
CM_ SG_ 1027 MHU_ChargingRequest "Request for VCU to ON/OFF Charging when schedule is reached";
CM_ SG_ 1027 MHU_ValetMode_Activation "Activate Valet mode from MHU";
CM_ SG_ 1027 MHU_ValetMode_MaxSpeed "Setting of maximum allowable in valet mode";
CM_ SG_ 807 MHU_CCU_AC_Button "Compressor Request Button";
CM_ SG_ 807 MHU_REC_Button "Loop mode Button";
CM_ SG_ 807 MHU_SetBlowMode "Set AC Mode";
CM_ SG_ 807 MHU_BlowerLevelSetting "Blower Level Setting";
CM_ SG_ 807 MHU_SetDriverTemp "Set Driver AC Temp level";
CM_ SG_ 807 MHU_ACM_Reserved "Air Conditioning PTC Switches(for new energy models with PTC only)";
CM_ SG_ 807 MHU_FrontDefrostReq_Reserved "Front Defrost Req";
CM_ SG_ 1058 Checksum_0x422 "Checksum";
CM_ SG_ 1058 Rolling_Counter_0x422 "Rolling_Counter";
CM_ SG_ 1058 MHU_STAT_DateTimeFormat "Indicate current date time format (12H and 24H)";
CM_ SG_ 1058 MHU_DISPLAY_STATUS "MHU for screen status";
CM_ SG_ 1058 MHU_STAT_Language "Indicate current Language";
CM_ SG_ 259 Q_Discharge "Negative";
CM_ SG_ 259 Q_Charge "Positive";
CM_ SG_ 259 RQ_DCDC_U "Voltage request for DCDC using power management";
CM_ SG_ 259 REQ_ConsumerControlAudioVolumeCo "Consumer control audio volume for powermanagement";
CM_ SG_ 259 REQ_CCU_PTC_Limitation "Consumer control PTC for powermanagement";
CM_ SG_ 1074 Checksum_0x432 "Checksum";
CM_ SG_ 1074 Rolling_Counter_0x432 "Rolling_Counter";
CM_ SG_ 1074 MHU_FOTA_State "FOTA global status";
CM_ SG_ 1074 MHU_FOTA_Error_Code "FOTA Error Code";
CM_ SG_ 1020 XGW_FOTA_StateConfirm "XGW FOTA global status confirmation";
CM_ SG_ 1020 XGW_FOTA_Error_Code "The signal FOTA Error Code indicates the status of the fota conditions:Bit 0:FOTA_MODE_COND_1: Vehicle StandstillBit 1:FOTA_MODE_COND_2: Low-voltage System VoltageBit 2:FOTA_MODE_COND_3: Engine/Motor is not runningBit 3:FOTA_MODE_COND_4: Last valid value of the signal MHU_FOTA_State signal is FOTA FLASHING or REMOTE DIAGNOSTICSBit 4:FOTA_MODE_COND_5: OBD diagnostic task not active.Bit 5:FOTA_MODE_COND_6: Ignition in start positionBit 6: Reserved. Set to 0 by default.Bit 7: Reserved. Set to 0 by default.00-----0: FOTA_MODE_COND_1 passed.00----0-: FOTA_MODE_COND_2 passed.00---0--: FOTA_MODE_COND_3 passed.00--0---: FOTA_MODE_COND_4 passed.00-0----: FOTA_MODE_COND_5 passed.000-----: FOTA_MODE_COND_6 passed.00-----1: FOTA_MODE_COND_1 failed.00----1-: FOTA_MODE_COND_2 failed.00---1--: FOTA_MODE_COND_3 failed.00--1---: FOTA_MODE_COND_4 failed.00-1----: FOTA_MODE_COND_5 failed.001-----: FOTA_MODE_COND_6 failed";
CM_ SG_ 1020 CRC_XGW_FOTA_StsConfirm "FOTA global status message checksum";
CM_ SG_ 1020 ALIV_XGW_FOTA_StsConfirm "FOTA global status message alive counter";
CM_ SG_ 1087 IPC_Sec "Represents the current second.60 - 63 = Invalid";
CM_ SG_ 1087 IPC_Min "Represents the current minute. 60 - 63 = Invalid";
CM_ SG_ 1087 IPC_Hour "Represents the current hour, 24 - 30 = not used";
CM_ SG_ 1087 IPC_Day "Represents the current dayInvalid value = 0";
CM_ SG_ 1087 IPC_Month "Represents the current month.0, 13 to 15 = Invalid";
CM_ SG_ 1087 IPC_Year "Represents the current year.";
CM_ SG_ 1087 IPC_SelfCheckStatus "Power on self check status";
CM_ SG_ 524 Checksum_0x20C "Checksum";
CM_ SG_ 524 Rolling_Counter_0x20C "Rolling_Counter";
CM_ SG_ 524 IPC_ODO "odograph";
CM_ SG_ 703 IPC_TripA "Set Trip A";
CM_ SG_ 703 IPC_AverageSpeedTripA "Average Speed of TripA";
CM_ SG_ 703 IPC_AverageConsumptionTripA "Average Consumption of TripA";
CM_ SG_ 703 IPC_ParkBrakeSts "Park Brake Status";
CM_ SG_ 703 IPC_VehSpd "Current Displayed Longitudinal Vehicle Speed";
CM_ SG_ 811 CCU_TemperatureGearSts "Temperature Gear Status";
CM_ SG_ 811 CCU_BlowMode_Sts "Blow Mode_Status";
CM_ SG_ 811 CCU_Circulation_Sts "CCU intake cycle state";
CM_ SG_ 811 CCU_AC_Req "Compressor request switch signal";
CM_ SG_ 811 CCU_AC_Sts "AC Status";
CM_ SG_ 811 CCU_BlowerLevelSts "Blower_Level";
CM_ SG_ 811 CCU_FrontDefrostSts "Defrost_Status";
CM_ SG_ 811 CCU_PTC_Req "CCU request VCU to enable or disable PTC";
CM_ SG_ 811 CCU_PTC_Temperature "PTC Temperature";
CM_ SG_ 811 CCU_CompSpdMEAS_Comp "Compressor speed signal";
CM_ SG_ 811 CCU_PollutionSts "Pollution mode state";
CM_ SG_ 811 CCU_ExternalTemperature "External Temperature";
CM_ SG_ 811 CCU_evaporator_Temperature "evaporator Temperature";
CM_ SG_ 811 CCU_ExternalTemperatureFailSts "External Temperature Fail Sts";
CM_ SG_ 133 Checksum_0x85 "Checksum";
CM_ SG_ 133 Rolling_Counter_0x85 "Rolling Counter";
CM_ SG_ 133 ACM_Crash_Sts "Crash status";
CM_ SG_ 133 ACM_Airbag_Deployment_Status "Signal to indicate if airbag/pretensioner/pyrofuse is deployed";
CM_ SG_ 133 ACM_Crash_Intensity "Indicate crash intensity level";
CM_ SG_ 133 ACM_Front_Crash "Output information for direction of crash";
CM_ SG_ 133 ACM_DriverSide_Crash "Output information for direction of crash";
CM_ SG_ 133 ACM_PassSide_Crash "Output information for direction of crash";
CM_ SG_ 133 ACM_Rear_Crash "Output information for direction of crash";
CM_ SG_ 133 ACM_Rollover_Crash "Output information for direction of crash";
CM_ SG_ 266 Checksum_0x10a "Checksum";
CM_ SG_ 266 Rolling_Counter_0x10a "Rolling_Counter";
CM_ SG_ 266 BCM_LVTop_up "LV  battery top up requice signal";
CM_ SG_ 266 Ubatt_Reserved "Battery Voltage(UBatt to be received by all modules,Required for DTC snapshots)";
CM_ SG_ 274 Checksum_0x112 "Checksum";
CM_ SG_ 274 Rolling_Counter_0x112 "Rolling_Counter";
CM_ SG_ 274 STAT_Terminal "Represent the status of physical terminal(STAT_Terminal to be received by all modules,Required for DTC snapshots and for FOTA)";
CM_ SG_ 274 STAT_CL30s_L_Reserved "Status Clamp 30s Logical ON/OFF";
CM_ SG_ 834 Checksum_0x342 "Check sum";
CM_ SG_ 834 Rolling_Counter_0x342 "Rolling Counter";
CM_ SG_ 834 ABS_LRWhlSpdRaw "Current Raw wheel speed information of rear left wheel.";
CM_ SG_ 834 ABS_LRWhlSpdRawValid "Current Raw wheel speed information valid flag of rear left wheel.";
CM_ SG_ 834 ABS_RRWhlSpdRaw "Current Raw wheel speed information of rear right wheel.,";
CM_ SG_ 834 ABS_RRWhlSpdRawValid "Current Raw wheel speed information valid flag of rear right wheel";
CM_ SG_ 834 ABS_VehSpd "Current Longitudinal Vehicle Speed";
CM_ SG_ 834 ABS_VehSpdValid "Speed Valid Flag";
CM_ SG_ 792 EAC_CompElecCurrV "Compressor Electrical Current Validity";
CM_ SG_ 792 EAC_CompStat "Compressor status";
CM_ SG_ 792 EAC_CompElecPwrV "Compressor Electrical Power Validity";
CM_ SG_ 792 EAC_CompSpdIncrReq "Compressor Speed Increasing Request";
CM_ SG_ 792 EAC_CompSpdV "Compressor Actual Speed Validity";
CM_ SG_ 792 EAC_CompElecPwr "Compressor Electrical Power";
CM_ SG_ 792 EAC_CompSpd "Compressor Actual Speed";
CM_ SG_ 792 EAC_CompElecCurr "Compressor Electrical Current";
CM_ SG_ 792 EAC_CompFltStat "Compressor Fault Status";
CM_ SG_ 937 VCU_PTC_RelaySts "PTC Relayopen or close state";
CM_ SG_ 937 VCU_EACEnbReq "The command of compressor,AC enable signal";
CM_ SG_ 937 VCU_EACAllowedPower "EAC Allowed Power";
CM_ SG_ 937 VCU_EAC_CompSpdReq "Compressor Speed Request";
CM_ SG_ 937 VCU_DriveCoolWaterFlowRate "Actual drive cool water flow rate";
CM_ SG_ 937 VCU_DriveCoolInletWaterTemp "The temperature of inlet radiator";
CM_ SG_ 441 VCU_MCUConsumepower "MCU Consume power";
CM_ SG_ 441 VCU_EACConsumepower "EAC Consume power";
CM_ SG_ 441 VCU_DCDCConsumepower "DCDC Consume power";
CM_ SG_ 441 VCU_PTCConsumepower "PTC Consume power";
CM_ SG_ 425 VCU_RegenLevel_Feed "VCU current Feedback Set power regenerative level";
CM_ SG_ 425 VCU_RBCSts "Regenerative Braking";
CM_ SG_ 425 VCU_RDCSts "Regenerative coasted";
CM_ SG_ 425 VCU_Veh_ERR "Vehicle System Error";
CM_ SG_ 425 VCU_DrvSys_ERR "DriveSystemError";
CM_ SG_ 425 VCU_PackSys_ERR "StoredEnergySystemError";
CM_ SG_ 425 VCU_TBOX_Veh_STS_Reserved "Vehicle Status";
CM_ SG_ 425 VCU_VehChg_STS "Vehicle Charge Status";
CM_ SG_ 425 VCU_BatterVoltage_Reserved "BetteryVoltage";
CM_ SG_ 425 VCU_BatteryVoltErr_Reserved "Indicate the generator is warning when Mechanical flag or Electrical flag is active (Reserved)（）";
CM_ SG_ 425 VCU_MotorCoolingCircuitErr_Reserved "Motor cooling loop failure state (Reserved)";
CM_ SG_ 425 VCU_PackCoolingCircuitErr_Reserved "Battery pack cooling loop failure state (Reserved)";
CM_ SG_ 425 VCU_VehicleHVStatus "Vehicle High voltage Ready State(VCU_VehicleHVStatus to be received by all modules,Used as a flash programming pre-condition (replacement for engine running)";
CM_ SG_ 425 VCU_InstantPowerConsump "Instant power consumption";
CM_ SG_ 425 VCU_AveragePowerConsump "Average power comsumption";
CM_ SG_ 425 VCU_BrakePedalSts "Brake Pedal Sts";
CM_ SG_ 1008 VCU_HVACInletWateTemp "HVAC inlet water temperature";
CM_ SG_ 1008 VCU_IMMO_Sts "IMMO staus";
CM_ SG_ 1008 VCU_DCDCAllowedPower "DCDCAllowedPower";
CM_ SG_ 1008 VCU_Shift_ERR "SCU file signal failure";
CM_ SG_ 1008 VCU_VehicleDischargePower "Discharge Power";
CM_ SG_ 1008 VCU_VehicleChargePower "Charge Power";
CM_ SG_ 533 Checksum_0x215 "Checksum";
CM_ SG_ 533 Rolling_Counter_0x215 "Rolling Counter";
CM_ SG_ 533 BMS_SOE "BMS State Of Enegy";
CM_ SG_ 533 BMS_HWCrash_Sts "Battery Pack Hardware Crash signal Status";
CM_ SG_ 533 BMS_HVIL_STS "The HVIL state of BMS";
CM_ SG_ 533 BMS_IGN_Sts "the ignition signal status (on/off)";
CM_ SG_ 533 BMS_Sys_STS "BMS_Status(Self-test after BMS wake-up)";
CM_ SG_ 533 BMS_HVOnOff_STS "BMS High Voltage Status(BMS_HVOnOff_STS to be received by all modules,Used as a flash programming pre-condition (replacement for engine running)";
CM_ SG_ 533 BMS_Balance_STS "BMS Balance Status";
CM_ SG_ 533 BMS_SocActual_EST "Actual SOC";
CM_ SG_ 533 BMS_BatBalance_ERR "Battery Balance Error indicates Balancing switch is short or open";
CM_ SG_ 533 BMS_ISU_Status "Insulation status";
CM_ SG_ 533 BMS_ERR_LEV "BMS requesting VCU to operate at the limited operating strategy (LOS)";
CM_ SG_ 533 BMS_SOH "BMS State Of Health";
CM_ SG_ 533 BMS_HV_Sts "BMS High Voltage Status";
CM_ SG_ 1284 MHU_sourceID "source ID";
CM_ SG_ 1284 MHU_CBV "CBV";
CM_ SG_ 1284 MHU_Data0 "Data0";
CM_ SG_ 1284 MHU_Data1 "Data1";
CM_ SG_ 1284 MHU_Data2 "Data2";
CM_ SG_ 1284 MHU_Data3 "Data3";
CM_ SG_ 1284 MHU_Data4 "Data4";
CM_ SG_ 1284 MHU_Data5 "Data5";
CM_ SG_ 1283 IPC_sourceID "source ID";
CM_ SG_ 1283 IPC_CBV "CBV";
CM_ SG_ 1283 IPC_Data0 "Data0";
CM_ SG_ 1283 IPC_Data1 "Data1";
CM_ SG_ 1283 IPC_Data2 "Data2";
CM_ SG_ 1283 IPC_Data3 "Data3";
CM_ SG_ 1283 IPC_Data4 "Data4";
CM_ SG_ 1283 IPC_Data5 "Data5";
CM_ SG_ 1282 GW_sourceID "source ID";
CM_ SG_ 1282 GW_CBV "CBV";
CM_ SG_ 1282 GW_Data0 "Data0";
CM_ SG_ 1282 GW_Data1 "Data1";
CM_ SG_ 1282 GW_Data2 "Data2";
CM_ SG_ 1282 GW_Data3 "Data3";
CM_ SG_ 1282 GW_Data4 "Data4";
CM_ SG_ 1282 GW_Data5 "Data5";
CM_ SG_ 1289 CCU_sourceID "source ID";
CM_ SG_ 1289 CCU_CBV "CBV";
CM_ SG_ 1289 CCU_Data0 "Data0";
CM_ SG_ 1289 CCU_Data1 "Data1";
CM_ SG_ 1289 CCU_Data2 "Data2";
CM_ SG_ 1289 CCU_Data3 "Data3";
CM_ SG_ 1289 CCU_Data4 "Data4";
CM_ SG_ 1289 CCU_Data5 "Data5";
CM_ SG_ 1673 CCU_DiagReqData0 "Data0";
CM_ SG_ 1673 CCU_DiagReqData1 "Data1";
CM_ SG_ 1673 CCU_DiagReqData2 "Data2";
CM_ SG_ 1673 CCU_DiagReqData3 "Data3";
CM_ SG_ 1673 CCU_DiagReqData4 "Data4";
CM_ SG_ 1673 CCU_DiagReqData5 "Data5";
CM_ SG_ 1673 CCU_DiagReqData6 "Data6";
CM_ SG_ 1673 CCU_DiagReqData7 "Data7";
CM_ SG_ 1545 CCU_DiagRespData0 "Data0";
CM_ SG_ 1545 CCU_DiagRespData1 "Data1";
CM_ SG_ 1545 CCU_DiagRespData2 "Data2";
CM_ SG_ 1545 CCU_DiagRespData3 "Data3";
CM_ SG_ 1545 CCU_DiagRespData4 "Data4";
CM_ SG_ 1545 CCU_DiagRespData5 "Data5";
CM_ SG_ 1545 CCU_DiagRespData6 "Data6";
CM_ SG_ 1545 CCU_DiagRespData7 "Data7";
CM_ SG_ 1791 GW_DiagFunctionalAddressingData0 "Data0";
CM_ SG_ 1791 GW_DiagFunctionalAddressingData1 "Data1";
CM_ SG_ 1791 GW_DiagFunctionalAddressingData2 "Data2";
CM_ SG_ 1791 GW_DiagFunctionalAddressingData3 "Data3";
CM_ SG_ 1791 GW_DiagFunctionalAddressingData4 "Data4";
CM_ SG_ 1791 GW_DiagFunctionalAddressingData5 "Data5";
CM_ SG_ 1791 GW_DiagFunctionalAddressingData6 "Data6";
CM_ SG_ 1791 GW_DiagFunctionalAddressingData7 "Data7";
BA_DEF_ BO_ "DiagRequest" ENUM "No","Yes";
BA_DEF_ BO_ "DiagResponse" ENUM "No","Yes";
BA_DEF_ BO_ "DiagState" ENUM "No","Yes";
BA_DEF_ BO_ "GenMsgCycleTime" INT 0 65535;
BA_DEF_ BO_ "GenMsgCycleTimeFast" INT 0 65535;
BA_DEF_ BO_ "GenMsgDelayTime" INT 0 65535;
BA_DEF_ BO_ "GenMsgILSupport" ENUM "No","Yes";
BA_DEF_ BO_ "GenMsgNrOfRepetition" INT 0 65535;
BA_DEF_ BO_ "GenMsgSendType" ENUM  "Cycle","Event","IfActive","CE","CA";
BA_DEF_ BO_ "NmAsrMessage" ENUM "No","Yes";
BA_DEF_ BO_ "NmMessage" ENUM "No","Yes";
BA_DEF_ SG_ "GenSigSendType" ENUM  "Cycle","OnWrite","OnWriteWithRepetition","OnChange","OnChangeWithRepetition","IfActive","IfActiveWithRepetition";
BA_DEF_ SG_ "GenSigStartValue" INT 0 2147483647;
BA_DEF_ SG_ "GenSigInvalidValue" INT 0 2147483647;
BA_DEF_ SG_ "GenSigInactiveValue" INT 0 2147483647;
BA_DEF_ BU_ "ILUsed" ENUM  "No","Yes";
BA_DEF_ BU_ "NmAsrCanMsgReducedTime" INT 320 640;
BA_DEF_ BU_ "NmAsrNode" ENUM  "No","Yes";
BA_DEF_  "Baudrate" INT 0 1000000;
BA_DEF_  "BusType" STRING;
BA_DEF_  "Manufacturer" STRING;
BA_DEF_  "NmAsrBaseAddress" HEX 0 2047;
BA_DEF_  "NmAsrCanMsgCycleTime" INT 0 65535;
BA_DEF_  "NmAsrMessageCount" INT 1 256;
BA_DEF_  "NmAsrRepeatMessageTime" INT 0 65535;
BA_DEF_  "NmAsrTimeoutTime" INT 0 65535;
BA_DEF_  "NmAsrWaitBusSleepTime" INT 0 65535;
BA_DEF_  "NmType" STRING;
BA_DEF_DEF_ "Baudrate" 500000;
BA_DEF_DEF_ "BusType" "CAN";
BA_DEF_DEF_ "DiagRequest" "No";
BA_DEF_DEF_ "DiagResponse" "No";
BA_DEF_DEF_ "DiagState" "No";
BA_DEF_DEF_ "GenMsgCycleTime" 0;
BA_DEF_DEF_ "GenMsgCycleTimeFast" 0;
BA_DEF_DEF_ "GenMsgDelayTime" 0;
BA_DEF_DEF_ "GenMsgILSupport" "Yes";
BA_DEF_DEF_ "GenMsgNrOfRepetition" 0;
BA_DEF_DEF_ "GenMsgSendType" "NoMsgSendType";
BA_DEF_DEF_ "GenSigSendType" "NoSigSendType";
BA_DEF_DEF_ "GenSigStartValue" 0;
BA_DEF_DEF_  "GenSigInvalidValue" 0;
BA_DEF_DEF_ "GenSigInactiveValue" 0;
BA_DEF_DEF_ "ILUsed" "Yes";
BA_DEF_DEF_ "Manufacturer" "Launch";
BA_DEF_DEF_ "NmAsrBaseAddress" 1280;
BA_DEF_DEF_ "NmAsrCanMsgCycleTime" 640;
BA_DEF_DEF_ "NmAsrCanMsgReducedTime" 320;
BA_DEF_DEF_ "NmAsrMessage" "No";
BA_DEF_DEF_ "NmAsrMessageCount" 128;
BA_DEF_DEF_ "NmAsrNode" "No";
BA_DEF_DEF_ "NmAsrRepeatMessageTime" 3200;
BA_DEF_DEF_ "NmAsrTimeoutTime" 2000;
BA_DEF_DEF_ "NmAsrWaitBusSleepTime" 1500;
BA_DEF_DEF_ "NmMessage" "No";
BA_DEF_DEF_ "NmType" "NmAsr";

BA_ "NmAsrNode" BU_ CCU 1;
BA_ "GenMsgSendType" BO_ 1027 3;
BA_ "GenMsgNrOfRepetition" BO_ 1027 5;
BA_ "GenMsgCycleTimeFast" BO_ 1027 20;
BA_ "GenMsgCycleTime" BO_ 1027 100;
BA_ "GenMsgSendType" BO_ 807 3;
BA_ "GenMsgNrOfRepetition" BO_ 807 5;
BA_ "GenMsgDelayTime" BO_ 807 10;
BA_ "GenMsgCycleTimeFast" BO_ 807 10;
BA_ "GenMsgCycleTime" BO_ 807 100;
BA_ "GenMsgSendType" BO_ 1058 0;
BA_ "GenMsgDelayTime" BO_ 1058 20;
BA_ "GenMsgCycleTime" BO_ 1058 100;
BA_ "GenMsgSendType" BO_ 259 0;
BA_ "GenMsgCycleTime" BO_ 259 200;
BA_ "GenMsgSendType" BO_ 1074 0;
BA_ "GenMsgDelayTime" BO_ 1074 50;
BA_ "GenMsgCycleTime" BO_ 1074 100;
BA_ "GenMsgSendType" BO_ 1020 0;
BA_ "GenMsgCycleTime" BO_ 1020 500;
BA_ "GenMsgSendType" BO_ 1087 0;
BA_ "GenMsgCycleTime" BO_ 1087 1000;
BA_ "GenMsgSendType" BO_ 524 0;
BA_ "GenMsgCycleTime" BO_ 524 100;
BA_ "GenMsgSendType" BO_ 703 0;
BA_ "GenMsgCycleTime" BO_ 703 50;
BA_ "GenMsgSendType" BO_ 811 0;
BA_ "GenMsgCycleTime" BO_ 811 50;
BA_ "GenMsgSendType" BO_ 133 0;
BA_ "GenMsgCycleTime" BO_ 133 20;
BA_ "GenMsgSendType" BO_ 266 0;
BA_ "GenMsgCycleTime" BO_ 266 100;
BA_ "GenMsgSendType" BO_ 274 0;
BA_ "GenMsgCycleTime" BO_ 274 100;
BA_ "GenMsgSendType" BO_ 834 0;
BA_ "GenMsgCycleTime" BO_ 834 10;
BA_ "GenMsgSendType" BO_ 792 0;
BA_ "GenMsgCycleTime" BO_ 792 50;
BA_ "GenMsgSendType" BO_ 937 0;
BA_ "GenMsgCycleTime" BO_ 937 20;
BA_ "GenMsgSendType" BO_ 441 0;
BA_ "GenMsgCycleTime" BO_ 441 50;
BA_ "GenMsgSendType" BO_ 425 0;
BA_ "GenMsgCycleTime" BO_ 425 20;
BA_ "GenMsgSendType" BO_ 1008 0;
BA_ "GenMsgCycleTime" BO_ 1008 20;
BA_ "GenMsgSendType" BO_ 533 0;
BA_ "GenMsgCycleTime" BO_ 533 50;
BA_ "GenMsgSendType" BO_ 1284 2;
BA_ "GenMsgCycleTime" BO_ 1284 640;
BA_ "NmAsrMessage" BO_ 1284 1;
BA_ "NmMessage" BO_ 1284 1;
BA_ "GenMsgSendType" BO_ 1283 2;
BA_ "GenMsgCycleTime" BO_ 1283 640;
BA_ "NmAsrMessage" BO_ 1283 1;
BA_ "NmMessage" BO_ 1283 1;
BA_ "GenMsgSendType" BO_ 1282 2;
BA_ "GenMsgCycleTime" BO_ 1282 640;
BA_ "NmAsrMessage" BO_ 1282 1;
BA_ "NmMessage" BO_ 1282 1;
BA_ "GenMsgSendType" BO_ 1289 2;
BA_ "GenMsgCycleTime" BO_ 1289 640;
BA_ "NmAsrMessage" BO_ 1289 1;
BA_ "NmMessage" BO_ 1289 1;
BA_ "GenMsgSendType" BO_ 1673 1;
BA_ "DiagRequest" BO_ 1673 1;
BA_ "GenMsgSendType" BO_ 1545 1;
BA_ "DiagResponse" BO_ 1545 1;
BA_ "GenMsgSendType" BO_ 1791 1;
BA_ "DiagState" BO_ 1791 1;
BA_ "GenSigSendType" SG_ 1027 Checksum_0x403 0;
BA_ "GenSigSendType" SG_ 1027 Rolling_Counter_0x403 0;
BA_ "GenSigInvalidValue" SG_ 1027 Rolling_Counter_0x403 15;
BA_ "GenSigSendType" SG_ 1027 MHU_SET_TCS_OnOff 2;
BA_ "GenSigInvalidValue" SG_ 1027 MHU_SET_TCS_OnOff 3;
BA_ "GenSigStartValue" SG_ 1027 MHU_SET_TCS_OnOff 2;
BA_ "GenSigSendType" SG_ 1027 MHU_SET_DrivingModeSwitch 2;
BA_ "GenSigSendType" SG_ 1027 MHU_SET_RegenLevel 2;
BA_ "GenSigStartValue" SG_ 1027 MHU_SET_RegenLevel 3;
BA_ "GenSigSendType" SG_ 1027 MHU_VCU_CreepDisable_stt 2;
BA_ "GenSigInvalidValue" SG_ 1027 MHU_VCU_CreepDisable_stt 3;
BA_ "GenSigStartValue" SG_ 1027 MHU_VCU_CreepDisable_stt 2;
BA_ "GenSigSendType" SG_ 1027 MHU_ChargeSetTargetSOC 2;
BA_ "GenSigInvalidValue" SG_ 1027 MHU_ChargeSetTargetSOC 127;
BA_ "GenSigStartValue" SG_ 1027 MHU_ChargeSetTargetSOC 100;
BA_ "GenSigSendType" SG_ 1027 MHU_HVACTurnON 2;
BA_ "GenSigInvalidValue" SG_ 1027 MHU_HVACTurnON 3;
BA_ "GenSigSendType" SG_ 1027 MHU_ChargeScheduleSet 2;
BA_ "GenSigStartValue" SG_ 1027 MHU_ChargeScheduleSet 2;
BA_ "GenSigSendType" SG_ 1027 MHU_ChargingRequest 2;
BA_ "GenSigStartValue" SG_ 1027 MHU_ChargingRequest 3;
BA_ "GenSigSendType" SG_ 1027 MHU_ValetMode_Activation 2;
BA_ "GenSigInvalidValue" SG_ 1027 MHU_ValetMode_Activation 254;
BA_ "GenSigInactiveValue" SG_ 1027 MHU_ValetMode_Activation 255;
BA_ "GenSigSendType" SG_ 1027 MHU_ValetMode_MaxSpeed 2;
BA_ "GenSigInvalidValue" SG_ 1027 MHU_ValetMode_MaxSpeed 2;
BA_ "GenSigInactiveValue" SG_ 1027 MHU_ValetMode_MaxSpeed 255;
BA_ "GenSigSendType" SG_ 807 MHU_CCU_AC_Button 2;
BA_ "GenSigInvalidValue" SG_ 807 MHU_CCU_AC_Button 3;
BA_ "GenSigSendType" SG_ 807 MHU_REC_Button 2;
BA_ "GenSigInvalidValue" SG_ 807 MHU_REC_Button 3;
BA_ "GenSigSendType" SG_ 807 MHU_SetBlowMode 2;
BA_ "GenSigInvalidValue" SG_ 807 MHU_SetBlowMode 7;
BA_ "GenSigSendType" SG_ 807 MHU_BlowerLevelSetting 2;
BA_ "GenSigInvalidValue" SG_ 807 MHU_BlowerLevelSetting 31;
BA_ "GenSigSendType" SG_ 807 MHU_SetDriverTemp 2;
BA_ "GenSigInvalidValue" SG_ 807 MHU_SetDriverTemp 63;
BA_ "GenSigSendType" SG_ 807 MHU_ACM_Reserved 2;
BA_ "GenSigInvalidValue" SG_ 807 MHU_ACM_Reserved 3;
BA_ "GenSigSendType" SG_ 807 MHU_FrontDefrostReq_Reserved 2;
BA_ "GenSigInvalidValue" SG_ 807 MHU_FrontDefrostReq_Reserved 3;
BA_ "GenSigSendType" SG_ 1058 Checksum_0x422 0;
BA_ "GenSigSendType" SG_ 1058 Rolling_Counter_0x422 0;
BA_ "GenSigInvalidValue" SG_ 1058 Rolling_Counter_0x422 15;
BA_ "GenSigSendType" SG_ 1058 MHU_STAT_DateTimeFormat 0;
BA_ "GenSigInvalidValue" SG_ 1058 MHU_STAT_DateTimeFormat 3;
BA_ "GenSigSendType" SG_ 1058 MHU_DISPLAY_STATUS 0;
BA_ "GenSigInvalidValue" SG_ 1058 MHU_DISPLAY_STATUS 3;
BA_ "GenSigSendType" SG_ 1058 MHU_STAT_Language 0;
BA_ "GenSigInvalidValue" SG_ 1058 MHU_STAT_Language 31;
BA_ "GenSigStartValue" SG_ 1058 MHU_STAT_Language 31;
BA_ "GenSigSendType" SG_ 259 Q_Discharge 0;
BA_ "GenSigSendType" SG_ 259 Q_Charge 0;
BA_ "GenSigSendType" SG_ 259 RQ_DCDC_U 0;
BA_ "GenSigSendType" SG_ 259 REQ_ConsumerControlAudioVolumeCo 0;
BA_ "GenSigSendType" SG_ 259 REQ_CCU_PTC_Limitation 0;
BA_ "GenSigSendType" SG_ 1074 Checksum_0x432 0;
BA_ "GenSigSendType" SG_ 1074 Rolling_Counter_0x432 0;
BA_ "GenSigInvalidValue" SG_ 1074 Rolling_Counter_0x432 15;
BA_ "GenSigSendType" SG_ 1074 MHU_FOTA_State 0;
BA_ "GenSigSendType" SG_ 1074 MHU_FOTA_Error_Code 0;
BA_ "GenSigSendType" SG_ 1020 XGW_FOTA_StateConfirm 0;
BA_ "GenSigSendType" SG_ 1020 XGW_FOTA_Error_Code 0;
BA_ "GenSigInvalidValue" SG_ 1020 XGW_FOTA_Error_Code 255;
BA_ "GenSigStartValue" SG_ 1020 XGW_FOTA_Error_Code 63;
BA_ "GenSigSendType" SG_ 1020 CRC_XGW_FOTA_StsConfirm 0;
BA_ "GenSigSendType" SG_ 1020 ALIV_XGW_FOTA_StsConfirm 0;
BA_ "GenSigSendType" SG_ 1087 IPC_Sec 0;
BA_ "GenSigInvalidValue" SG_ 1087 IPC_Sec 63;
BA_ "GenSigSendType" SG_ 1087 IPC_Min 0;
BA_ "GenSigInvalidValue" SG_ 1087 IPC_Min 63;
BA_ "GenSigSendType" SG_ 1087 IPC_Hour 0;
BA_ "GenSigInvalidValue" SG_ 1087 IPC_Hour 31;
BA_ "GenSigSendType" SG_ 1087 IPC_Day 0;
BA_ "GenSigInvalidValue" SG_ 1087 IPC_Day 31;
BA_ "GenSigStartValue" SG_ 1087 IPC_Day 1;
BA_ "GenSigSendType" SG_ 1087 IPC_Month 0;
BA_ "GenSigInvalidValue" SG_ 1087 IPC_Month 15;
BA_ "GenSigStartValue" SG_ 1087 IPC_Month 1;
BA_ "GenSigSendType" SG_ 1087 IPC_Year 0;
BA_ "GenSigInvalidValue" SG_ 1087 IPC_Year 255;
BA_ "GenSigSendType" SG_ 1087 IPC_SelfCheckStatus 0;
BA_ "GenSigSendType" SG_ 524 Checksum_0x20C 0;
BA_ "GenSigSendType" SG_ 524 Rolling_Counter_0x20C 0;
BA_ "GenSigInvalidValue" SG_ 524 Rolling_Counter_0x20C 15;
BA_ "GenSigSendType" SG_ 524 IPC_ODO 0;
BA_ "GenSigInvalidValue" SG_ 524 IPC_ODO 1048575;
BA_ "GenSigSendType" SG_ 703 IPC_TripA 0;
BA_ "GenSigInvalidValue" SG_ 703 IPC_TripA 65535;
BA_ "GenSigSendType" SG_ 703 IPC_AverageSpeedTripA 0;
BA_ "GenSigInvalidValue" SG_ 703 IPC_AverageSpeedTripA 4095;
BA_ "GenSigSendType" SG_ 703 IPC_AverageConsumptionTripA 0;
BA_ "GenSigInvalidValue" SG_ 703 IPC_AverageConsumptionTripA 1023;
BA_ "GenSigSendType" SG_ 703 IPC_ParkBrakeSts 0;
BA_ "GenSigInvalidValue" SG_ 703 IPC_ParkBrakeSts 3;
BA_ "GenSigSendType" SG_ 703 IPC_VehSpd 0;
BA_ "GenSigInvalidValue" SG_ 703 IPC_VehSpd 32767;
BA_ "GenSigSendType" SG_ 811 CCU_TemperatureGearSts 0;
BA_ "GenSigInvalidValue" SG_ 811 CCU_TemperatureGearSts 63;
BA_ "GenSigStartValue" SG_ 811 CCU_TemperatureGearSts 7;
BA_ "GenSigSendType" SG_ 811 CCU_BlowMode_Sts 0;
BA_ "GenSigInvalidValue" SG_ 811 CCU_BlowMode_Sts 7;
BA_ "GenSigStartValue" SG_ 811 CCU_BlowMode_Sts 2;
BA_ "GenSigSendType" SG_ 811 CCU_Circulation_Sts 0;
BA_ "GenSigSendType" SG_ 811 CCU_AC_Req 0;
BA_ "GenSigInvalidValue" SG_ 811 CCU_AC_Req 3;
BA_ "GenSigSendType" SG_ 811 CCU_AC_Sts 0;
BA_ "GenSigSendType" SG_ 811 CCU_BlowerLevelSts 0;
BA_ "GenSigStartValue" SG_ 811 CCU_BlowerLevelSts 1;
BA_ "GenSigSendType" SG_ 811 CCU_FrontDefrostSts 0;
BA_ "GenSigSendType" SG_ 811 CCU_PTC_Req 0;
BA_ "GenSigInvalidValue" SG_ 811 CCU_PTC_Req 3;
BA_ "GenSigSendType" SG_ 811 CCU_PTC_Temperature 0;
BA_ "GenSigInvalidValue" SG_ 811 CCU_PTC_Temperature 1023;
BA_ "GenSigSendType" SG_ 811 CCU_CompSpdMEAS_Comp 0;
BA_ "GenSigInvalidValue" SG_ 811 CCU_CompSpdMEAS_Comp 8191;
BA_ "GenSigSendType" SG_ 811 CCU_PollutionSts 0;
BA_ "GenSigSendType" SG_ 811 CCU_ExternalTemperature 0;
BA_ "GenSigInvalidValue" SG_ 811 CCU_ExternalTemperature 255;
BA_ "GenSigStartValue" SG_ 811 CCU_ExternalTemperature 255;
BA_ "GenSigSendType" SG_ 811 CCU_evaporator_Temperature 0;
BA_ "GenSigInvalidValue" SG_ 811 CCU_evaporator_Temperature 31;
BA_ "GenSigStartValue" SG_ 811 CCU_evaporator_Temperature 10;
BA_ "GenSigSendType" SG_ 811 CCU_ExternalTemperatureFailSts 0;
BA_ "GenSigInvalidValue" SG_ 811 CCU_ExternalTemperatureFailSts 1;
BA_ "GenSigStartValue" SG_ 811 CCU_ExternalTemperatureFailSts 1;
BA_ "GenSigSendType" SG_ 133 Checksum_0x85 0;
BA_ "GenSigSendType" SG_ 133 Rolling_Counter_0x85 0;
BA_ "GenSigInvalidValue" SG_ 133 Rolling_Counter_0x85 15;
BA_ "GenSigSendType" SG_ 133 ACM_Crash_Sts 0;
BA_ "GenSigSendType" SG_ 133 ACM_Airbag_Deployment_Status 0;
BA_ "GenSigSendType" SG_ 133 ACM_Crash_Intensity 0;
BA_ "GenSigSendType" SG_ 133 ACM_Front_Crash 0;
BA_ "GenSigSendType" SG_ 133 ACM_DriverSide_Crash 0;
BA_ "GenSigSendType" SG_ 133 ACM_PassSide_Crash 0;
BA_ "GenSigSendType" SG_ 133 ACM_Rear_Crash 0;
BA_ "GenSigSendType" SG_ 133 ACM_Rollover_Crash 0;
BA_ "GenSigSendType" SG_ 266 Checksum_0x10a 0;
BA_ "GenSigSendType" SG_ 266 Rolling_Counter_0x10a 0;
BA_ "GenSigInvalidValue" SG_ 266 Rolling_Counter_0x10a 15;
BA_ "GenSigSendType" SG_ 266 BCM_LVTop_up 0;
BA_ "GenSigSendType" SG_ 266 Ubatt_Reserved 0;
BA_ "GenSigInvalidValue" SG_ 266 Ubatt_Reserved 16383;
BA_ "GenSigStartValue" SG_ 266 Ubatt_Reserved 9000;
BA_ "GenSigSendType" SG_ 274 Checksum_0x112 0;
BA_ "GenSigSendType" SG_ 274 Rolling_Counter_0x112 0;
BA_ "GenSigInvalidValue" SG_ 274 Rolling_Counter_0x112 15;
BA_ "GenSigSendType" SG_ 274 STAT_Terminal 0;
BA_ "GenSigSendType" SG_ 274 STAT_CL30s_L_Reserved 0;
BA_ "GenSigStartValue" SG_ 274 STAT_CL30s_L_Reserved 3;
BA_ "GenSigSendType" SG_ 834 Checksum_0x342 0;
BA_ "GenSigSendType" SG_ 834 Rolling_Counter_0x342 0;
BA_ "GenSigInvalidValue" SG_ 834 Rolling_Counter_0x342 15;
BA_ "GenSigSendType" SG_ 834 ABS_LRWhlSpdRaw 0;
BA_ "GenSigInvalidValue" SG_ 834 ABS_LRWhlSpdRaw 32767;
BA_ "GenSigSendType" SG_ 834 ABS_LRWhlSpdRawValid 0;
BA_ "GenSigSendType" SG_ 834 ABS_RRWhlSpdRaw 0;
BA_ "GenSigInvalidValue" SG_ 834 ABS_RRWhlSpdRaw 32767;
BA_ "GenSigSendType" SG_ 834 ABS_RRWhlSpdRawValid 0;
BA_ "GenSigSendType" SG_ 834 ABS_VehSpd 0;
BA_ "GenSigInvalidValue" SG_ 834 ABS_VehSpd 32767;
BA_ "GenSigSendType" SG_ 834 ABS_VehSpdValid 0;
BA_ "GenSigSendType" SG_ 792 EAC_CompElecCurrV 0;
BA_ "GenSigInvalidValue" SG_ 792 EAC_CompElecCurrV 1;
BA_ "GenSigSendType" SG_ 792 EAC_CompStat 0;
BA_ "GenSigInvalidValue" SG_ 792 EAC_CompStat 15;
BA_ "GenSigStartValue" SG_ 792 EAC_CompStat 2;
BA_ "GenSigSendType" SG_ 792 EAC_CompElecPwrV 0;
BA_ "GenSigInvalidValue" SG_ 792 EAC_CompElecPwrV 1;
BA_ "GenSigSendType" SG_ 792 EAC_CompSpdIncrReq 0;
BA_ "GenSigSendType" SG_ 792 EAC_CompSpdV 0;
BA_ "GenSigInvalidValue" SG_ 792 EAC_CompSpdV 1;
BA_ "GenSigSendType" SG_ 792 EAC_CompElecPwr 0;
BA_ "GenSigInvalidValue" SG_ 792 EAC_CompElecPwr 255;
BA_ "GenSigSendType" SG_ 792 EAC_CompSpd 0;
BA_ "GenSigInvalidValue" SG_ 792 EAC_CompSpd 16383;
BA_ "GenSigSendType" SG_ 792 EAC_CompElecCurr 0;
BA_ "GenSigInvalidValue" SG_ 792 EAC_CompElecCurr 255;
BA_ "GenSigSendType" SG_ 792 EAC_CompFltStat 0;
BA_ "GenSigInvalidValue" SG_ 792 EAC_CompFltStat 15;
BA_ "GenSigSendType" SG_ 937 VCU_PTC_RelaySts 0;
BA_ "GenSigSendType" SG_ 937 VCU_EACEnbReq 0;
BA_ "GenSigSendType" SG_ 937 VCU_EACAllowedPower 0;
BA_ "GenSigInvalidValue" SG_ 937 VCU_EACAllowedPower 1023;
BA_ "GenSigSendType" SG_ 937 VCU_EAC_CompSpdReq 0;
BA_ "GenSigInvalidValue" SG_ 937 VCU_EAC_CompSpdReq 16383;
BA_ "GenSigSendType" SG_ 937 VCU_DriveCoolWaterFlowRate 0;
BA_ "GenSigSendType" SG_ 937 VCU_DriveCoolInletWaterTemp 0;
BA_ "GenSigSendType" SG_ 441 VCU_MCUConsumepower 0;
BA_ "GenSigSendType" SG_ 441 VCU_EACConsumepower 0;
BA_ "GenSigSendType" SG_ 441 VCU_DCDCConsumepower 0;
BA_ "GenSigSendType" SG_ 441 VCU_PTCConsumepower 0;
BA_ "GenSigSendType" SG_ 425 VCU_RegenLevel_Feed 0;
BA_ "GenSigStartValue" SG_ 425 VCU_RegenLevel_Feed 2;
BA_ "GenSigSendType" SG_ 425 VCU_RBCSts 0;
BA_ "GenSigSendType" SG_ 425 VCU_RDCSts 0;
BA_ "GenSigSendType" SG_ 425 VCU_Veh_ERR 0;
BA_ "GenSigSendType" SG_ 425 VCU_DrvSys_ERR 0;
BA_ "GenSigSendType" SG_ 425 VCU_PackSys_ERR 0;
BA_ "GenSigSendType" SG_ 425 VCU_TBOX_Veh_STS_Reserved 0;
BA_ "GenSigSendType" SG_ 425 VCU_VehChg_STS 0;
BA_ "GenSigSendType" SG_ 425 VCU_BatterVoltage_Reserved 0;
BA_ "GenSigInvalidValue" SG_ 425 VCU_BatterVoltage_Reserved 255;
BA_ "GenSigStartValue" SG_ 425 VCU_BatterVoltage_Reserved 171;
BA_ "GenSigSendType" SG_ 425 VCU_BatteryVoltErr_Reserved 0;
BA_ "GenSigSendType" SG_ 425 VCU_MotorCoolingCircuitErr_Reserved 0;
BA_ "GenSigSendType" SG_ 425 VCU_PackCoolingCircuitErr_Reserved 0;
BA_ "GenSigSendType" SG_ 425 VCU_VehicleHVStatus 0;
BA_ "GenSigInvalidValue" SG_ 425 VCU_VehicleHVStatus 3;
BA_ "GenSigSendType" SG_ 425 VCU_InstantPowerConsump 0;
BA_ "GenSigInvalidValue" SG_ 425 VCU_InstantPowerConsump 1023;
BA_ "GenSigSendType" SG_ 425 VCU_AveragePowerConsump 0;
BA_ "GenSigInvalidValue" SG_ 425 VCU_AveragePowerConsump 1023;
BA_ "GenSigSendType" SG_ 425 VCU_BrakePedalSts 0;
BA_ "GenSigSendType" SG_ 1008 VCU_HVACInletWateTemp 0;
BA_ "GenSigInvalidValue" SG_ 1008 VCU_HVACInletWateTemp 255;
BA_ "GenSigStartValue" SG_ 1008 VCU_HVACInletWateTemp 40;
BA_ "GenSigSendType" SG_ 1008 VCU_IMMO_Sts 0;
BA_ "GenSigInvalidValue" SG_ 1008 VCU_IMMO_Sts 2;
BA_ "GenSigSendType" SG_ 1008 VCU_DCDCAllowedPower 0;
BA_ "GenSigInvalidValue" SG_ 1008 VCU_DCDCAllowedPower 511;
BA_ "GenSigSendType" SG_ 1008 VCU_Shift_ERR 0;
BA_ "GenSigSendType" SG_ 1008 VCU_VehicleDischargePower 0;
BA_ "GenSigInvalidValue" SG_ 1008 VCU_VehicleDischargePower 127;
BA_ "GenSigSendType" SG_ 1008 VCU_VehicleChargePower 0;
BA_ "GenSigInvalidValue" SG_ 1008 VCU_VehicleChargePower 127;
BA_ "GenSigSendType" SG_ 533 Checksum_0x215 0;
BA_ "GenSigSendType" SG_ 533 Rolling_Counter_0x215 0;
BA_ "GenSigInvalidValue" SG_ 533 Rolling_Counter_0x215 15;
BA_ "GenSigSendType" SG_ 533 BMS_SOE 0;
BA_ "GenSigInvalidValue" SG_ 533 BMS_SOE 255;
BA_ "GenSigStartValue" SG_ 533 BMS_SOE 54;
BA_ "GenSigSendType" SG_ 533 BMS_HWCrash_Sts 0;
BA_ "GenSigSendType" SG_ 533 BMS_HVIL_STS 0;
BA_ "GenSigSendType" SG_ 533 BMS_IGN_Sts 0;
BA_ "GenSigSendType" SG_ 533 BMS_Sys_STS 0;
BA_ "GenSigInvalidValue" SG_ 533 BMS_Sys_STS 8;
BA_ "GenSigSendType" SG_ 533 BMS_HVOnOff_STS 0;
BA_ "GenSigSendType" SG_ 533 BMS_Balance_STS 0;
BA_ "GenSigSendType" SG_ 533 BMS_SocActual_EST 0;
BA_ "GenSigInvalidValue" SG_ 533 BMS_SocActual_EST 1023;
BA_ "GenSigSendType" SG_ 533 BMS_BatBalance_ERR 0;
BA_ "GenSigSendType" SG_ 533 BMS_ISU_Status 0;
BA_ "GenSigSendType" SG_ 533 BMS_ERR_LEV 0;
BA_ "GenSigInvalidValue" SG_ 533 BMS_ERR_LEV 15;
BA_ "GenSigSendType" SG_ 533 BMS_SOH 0;
BA_ "GenSigInvalidValue" SG_ 533 BMS_SOH 255;
BA_ "GenSigStartValue" SG_ 533 BMS_SOH 54;
BA_ "GenSigSendType" SG_ 533 BMS_HV_Sts 0;
BA_ "GenSigSendType" SG_ 1284 MHU_sourceID 0;
BA_ "GenSigSendType" SG_ 1284 MHU_CBV 0;
BA_ "GenSigSendType" SG_ 1284 MHU_Data0 0;
BA_ "GenSigSendType" SG_ 1284 MHU_Data1 0;
BA_ "GenSigSendType" SG_ 1284 MHU_Data2 0;
BA_ "GenSigSendType" SG_ 1284 MHU_Data3 0;
BA_ "GenSigSendType" SG_ 1284 MHU_Data4 0;
BA_ "GenSigSendType" SG_ 1284 MHU_Data5 0;
BA_ "GenSigSendType" SG_ 1283 IPC_sourceID 0;
BA_ "GenSigSendType" SG_ 1283 IPC_CBV 0;
BA_ "GenSigSendType" SG_ 1283 IPC_Data0 0;
BA_ "GenSigSendType" SG_ 1283 IPC_Data1 0;
BA_ "GenSigSendType" SG_ 1283 IPC_Data2 0;
BA_ "GenSigSendType" SG_ 1283 IPC_Data3 0;
BA_ "GenSigSendType" SG_ 1283 IPC_Data4 0;
BA_ "GenSigSendType" SG_ 1283 IPC_Data5 0;
BA_ "GenSigSendType" SG_ 1282 GW_sourceID 0;
BA_ "GenSigSendType" SG_ 1282 GW_CBV 0;
BA_ "GenSigSendType" SG_ 1282 GW_Data0 0;
BA_ "GenSigSendType" SG_ 1282 GW_Data1 0;
BA_ "GenSigSendType" SG_ 1282 GW_Data2 0;
BA_ "GenSigSendType" SG_ 1282 GW_Data3 0;
BA_ "GenSigSendType" SG_ 1282 GW_Data4 0;
BA_ "GenSigSendType" SG_ 1282 GW_Data5 0;
BA_ "GenSigSendType" SG_ 1289 CCU_sourceID 0;
BA_ "GenSigSendType" SG_ 1289 CCU_CBV 0;
BA_ "GenSigSendType" SG_ 1289 CCU_Data0 0;
BA_ "GenSigSendType" SG_ 1289 CCU_Data1 0;
BA_ "GenSigSendType" SG_ 1289 CCU_Data2 0;
BA_ "GenSigSendType" SG_ 1289 CCU_Data3 0;
BA_ "GenSigSendType" SG_ 1289 CCU_Data4 0;
BA_ "GenSigSendType" SG_ 1289 CCU_Data5 0;
BA_ "GenSigSendType" SG_ 1673 CCU_DiagReqData0 0;
BA_ "GenSigSendType" SG_ 1673 CCU_DiagReqData1 0;
BA_ "GenSigSendType" SG_ 1673 CCU_DiagReqData2 0;
BA_ "GenSigSendType" SG_ 1673 CCU_DiagReqData3 0;
BA_ "GenSigSendType" SG_ 1673 CCU_DiagReqData4 0;
BA_ "GenSigSendType" SG_ 1673 CCU_DiagReqData5 0;
BA_ "GenSigSendType" SG_ 1673 CCU_DiagReqData6 0;
BA_ "GenSigSendType" SG_ 1673 CCU_DiagReqData7 0;
BA_ "GenSigSendType" SG_ 1545 CCU_DiagRespData0 0;
BA_ "GenSigSendType" SG_ 1545 CCU_DiagRespData1 0;
BA_ "GenSigSendType" SG_ 1545 CCU_DiagRespData2 0;
BA_ "GenSigSendType" SG_ 1545 CCU_DiagRespData3 0;
BA_ "GenSigSendType" SG_ 1545 CCU_DiagRespData4 0;
BA_ "GenSigSendType" SG_ 1545 CCU_DiagRespData5 0;
BA_ "GenSigSendType" SG_ 1545 CCU_DiagRespData6 0;
BA_ "GenSigSendType" SG_ 1545 CCU_DiagRespData7 0;
BA_ "GenSigSendType" SG_ 1791 GW_DiagFunctionalAddressingData0 0;
BA_ "GenSigSendType" SG_ 1791 GW_DiagFunctionalAddressingData1 0;
BA_ "GenSigSendType" SG_ 1791 GW_DiagFunctionalAddressingData2 0;
BA_ "GenSigSendType" SG_ 1791 GW_DiagFunctionalAddressingData3 0;
BA_ "GenSigSendType" SG_ 1791 GW_DiagFunctionalAddressingData4 0;
BA_ "GenSigSendType" SG_ 1791 GW_DiagFunctionalAddressingData5 0;
BA_ "GenSigSendType" SG_ 1791 GW_DiagFunctionalAddressingData6 0;
BA_ "GenSigSendType" SG_ 1791 GW_DiagFunctionalAddressingData7 0;
VAL_ 1027 Rolling_Counter_0x403 15 "Invalid";
VAL_ 1027 MHU_SET_TCS_OnOff 0 "OFF (keep sending for 2 seconds)" 1 "ON (keep sending for 2 seconds)" 2 "No action" 3 "Invalid";
VAL_ 1027 MHU_SET_DrivingModeSwitch 3 "sport mode (should be hold during 1 second)" 2 "normal mode (should be hold during 1 second)" 1 "eco mode (should be hold during 1 second)" 0 "no change request";
VAL_ 1027 MHU_SET_RegenLevel 3 "No action" 2 "High" 1 "Low" 0 "none";
VAL_ 1027 MHU_VCU_CreepDisable_stt 0 "No request" 1 "Creep Disable request" 2 "Reserved" 3 "Invalid";
VAL_ 1027 MHU_HVACTurnON 0 "No request" 1 "ON" 2 "Reserved" 3 "Invalid";
VAL_ 1027 MHU_ChargeScheduleSet 0 "Disabled" 1 "Enabled" 2 "No Action" 3 "Reserved";
VAL_ 1027 MHU_ChargingRequest 0 "Reserved" 1 "Request scheduled start charging" 2 "Request stop" 3 "No effect";
VAL_ 1027 MHU_ValetMode_Activation 0 "Inactive" 1 "Active" 254 "Reserved" 255 "Invalid";
VAL_ 807 MHU_CCU_AC_Button 3 "Invalid" 1 "Press" 0 "Release";
VAL_ 807 MHU_REC_Button 3 "Invalid" 1 "Press" 0 "Release";
VAL_ 807 MHU_SetBlowMode 7 "Invalid" 6 "Reserve" 5 "Reserve" 4 "Foot and window" 3 "Foot" 2 "foot and face" 1 "face" 0 "Inactive";
VAL_ 807 MHU_BlowerLevelSetting 9 "level 8" 8 "level 7" 7 "level 6" 6 "level 5" 5 "level 4" 4 "level 3" 3 "level 2" 2 "level 1" 1 "OFF" 0 "Inactive";
VAL_ 807 MHU_SetDriverTemp 63 "Invalid" 16 "level 8" 15 "level 7" 14 "level 6" 13 "level 5" 12 "level 4" 11 "level 3" 10 "level 2" 9 "level 1" 8 "level 8" 7 "level 7" 6 "level 6" 5 "level 5" 4 "level 4" 3 "level 3" 2 "level 2" 1 "level 1" 0 "Inactive";
VAL_ 807 MHU_ACM_Reserved 3 "Invalid" 1 "Active" 0 "Inactive";
VAL_ 807 MHU_FrontDefrostReq_Reserved 3 "Invalid" 1 "Active" 0 "Inactive";
VAL_ 1058 Rolling_Counter_0x422 15 "Invalid";
VAL_ 1058 MHU_STAT_DateTimeFormat 3 "Signal invalid" 2 "Reserved" 1 "12H" 0 "24H";
VAL_ 1058 MHU_DISPLAY_STATUS 0 "OFF" 1 "ON" 2 "Reserved" 3 "Invalid";
VAL_ 1058 MHU_STAT_Language 31 "Signal invalid" 30 "Reserved" 29 "Reserved" 28 "Reserved" 27 "Reserved" 26 "Reserved" 25 "Reserved" 24 "Reserved" 23 "Reserved" 22 "Reserved" 21 "Reserved" 20 "Reserved" 19 "Reserved" 18 "Reserved" 17 "Reserved" 16 "Reserved" 15 "Reserved" 14 "Reserved" 13 "Reserved" 12 "Reserved" 11 "Reserved" 10 "Reserved" 9 "Reserved" 8 "Reserved" 7 "Reserved" 6 "Cambodia" 5 "Laos" 4 "Indonesian" 3 "Thai" 2 "Malay" 1 "English" 0 "Vietnamese";
VAL_ 259 REQ_ConsumerControlAudioVolumeCo 7 "signal invalid" 6 "Reserved" 5 "Reserved" 4 "Reserved" 3 "Reserved" 2 "Level 2" 1 "Level 1" 0 "No Reduction";
VAL_ 1074 Rolling_Counter_0x432 15 "Invalid";
VAL_ 1074 MHU_FOTA_State 0 "INIT" 1 "NORMAL" 2 "FOTA FLASHING" 3 "FOTA-SUSPENDED" 4 "FAIL-SAFE-ERROR" 5 "SHUTDOWN" 6 "REMOTE DIAGNOSTICS" 7 "Invalid";
VAL_ 1020 XGW_FOTA_StateConfirm 0 "INIT" 1 "NORMAL" 2 "FOTA FLASHING" 3 "FOTA-SUSPENDED" 4 "FAIL-SAFE-ERROR" 5 "SHUTDOWN" 6 "REMOTE DIAGNOSTICS" 7 "Invalid";
VAL_ 1087 IPC_Sec 63 "Invalid";
VAL_ 1087 IPC_Min 63 "Invalid";
VAL_ 1087 IPC_Hour 31 "Invalid";
VAL_ 1087 IPC_Day 31 "Invalid";
VAL_ 1087 IPC_Month 15 "Invalid";
VAL_ 1087 IPC_Year 255 "Invalid";
VAL_ 1087 IPC_SelfCheckStatus 1 "self-check finish" 0 "self-checking";
VAL_ 524 Rolling_Counter_0x20C 15 "Invalid";
VAL_ 524 IPC_ODO 1048575 "Invalid";
VAL_ 703 IPC_TripA 65535 "Invalid";
VAL_ 703 IPC_AverageSpeedTripA 4095 "Invalid";
VAL_ 703 IPC_AverageConsumptionTripA 1023 "Invalid";
VAL_ 703 IPC_ParkBrakeSts 3 "Invalid" 2 "Reserved" 1 "Applied" 0 "Released";
VAL_ 703 IPC_VehSpd 32767 "Invalid";
VAL_ 811 CCU_TemperatureGearSts 63 "Invalid" 16 "level 8" 15 "level 7" 14 "level 6" 13 "level 5" 12 "level 4" 11 "level 3" 10 "level 2" 9 "level 1" 8 "level 8" 7 "level 7" 6 "level 6" 5 "level 5" 4 "level 4" 3 "level 3" 2 "level 2" 1 "level 1" 0 "Inactive";
VAL_ 811 CCU_BlowMode_Sts 7 "Invalid" 6 "Reserve" 4 "Foot and window" 3 "Foot" 2 "Foot and Face" 1 "Face" 0 "OFF";
VAL_ 811 CCU_Circulation_Sts 1 "Internal circulation" 0 "Outer circulation";
VAL_ 811 CCU_AC_Req 3 "Invalid" 2 "Reserved" 1 "Requset" 0 "No requset";
VAL_ 811 CCU_AC_Sts 1 "ON" 0 "OFF";
VAL_ 811 CCU_BlowerLevelSts 8 "level 8" 7 "level 7" 6 "level 6" 5 "level 5" 4 "level 4" 3 "level 3" 2 "level 2" 1 "level 1" 0 "OFF";
VAL_ 811 CCU_FrontDefrostSts 1 "On" 0 "Off";
VAL_ 811 CCU_PTC_Req 3 "Invalid" 2 "Reserved" 1 "Requset" 0 "No requset";
VAL_ 811 CCU_PTC_Temperature 1023 "Invaild";
VAL_ 811 CCU_CompSpdMEAS_Comp 8191 "Invalid";
VAL_ 811 CCU_PollutionSts 1 "ON" 0 "OFF";
VAL_ 811 CCU_ExternalTemperature 255 "Invaild";
VAL_ 811 CCU_evaporator_Temperature 31 "Invalid";
VAL_ 811 CCU_ExternalTemperatureFailSts 1 "invalid" 0 "valid";
VAL_ 133 Rolling_Counter_0x85 15 "Invalid";
VAL_ 133 ACM_Crash_Sts 3 "Invalid Value" 2 "Invalid Value" 1 "Crash_Detected" 0 "No_Event";
VAL_ 133 ACM_Airbag_Deployment_Status 3 "Invalid Value" 2 "Invalid Value" 1 "Airbag_Deployment" 0 "No_Airbag_Deployment";
VAL_ 133 ACM_Crash_Intensity 7 "Invalid_Value" 6 "Invalid_Value" 5 "Invalid_Value" 4 "Invalid_Value" 3 "Crash_Intensity_3" 2 "Crash_Intensity_2" 1 "Crash_Intensity_1" 0 "No_Crash";
VAL_ 133 ACM_Front_Crash 3 "Invalid Value" 2 "Invalid Value" 1 "Front_Crash_Detected" 0 "No_Event";
VAL_ 133 ACM_DriverSide_Crash 3 "Invalid Value" 2 "Invalid Value" 1 "Driverside_Crash_Detected" 0 "No_Event";
VAL_ 133 ACM_PassSide_Crash 3 "Invalid Value" 2 "Invalid Value" 1 "PassSide_Crash_Detected" 0 "No_Event";
VAL_ 133 ACM_Rear_Crash 3 "Invalid Value" 2 "Invalid Value" 1 "Rear_Crash_Detected" 0 "No_Event";
VAL_ 133 ACM_Rollover_Crash 3 "Invalid Value" 2 "Invalid Value" 1 "Rollover_Crash_Detected" 0 "No_Event";
VAL_ 266 Rolling_Counter_0x10a 15 "Invalid";
VAL_ 266 BCM_LVTop_up 1 "start Top up" 0 "stop Top up";
VAL_ 274 Rolling_Counter_0x112 15 "Invalid";
VAL_ 274 STAT_Terminal 7 "Signal invalid" 6 "Reserved" 5 "Reserved" 4 "SW update OTA (Not used in VFe34)" 3 "Engine start (eMotor running)" 2 "ON (Driver Present)" 1 "ACC (Park)" 0 "OFF(Comfort Enable)";
VAL_ 274 STAT_CL30s_L_Reserved 3 "Signal invalid" 2 "Failure" 1 "ON" 0 "OFF";
VAL_ 834 Rolling_Counter_0x342 15 "Invalid";
VAL_ 834 ABS_LRWhlSpdRaw 32767 "Invalid";
VAL_ 834 ABS_LRWhlSpdRawValid 1 "Valid" 0 "Invalid";
VAL_ 834 ABS_RRWhlSpdRaw 32767 "Invalid";
VAL_ 834 ABS_RRWhlSpdRawValid 1 "Valid" 0 "Invalid";
VAL_ 834 ABS_VehSpd 32767 "Invalid";
VAL_ 834 ABS_VehSpdValid 1 "Valid" 0 "Invalid";
VAL_ 792 EAC_CompElecCurrV 0 "Valid" 1 "Invalid";
VAL_ 792 EAC_CompStat 0 "Normal Operation" 1 "Degraded Operation" 2 "Inoperative" 15 "Invalid";
VAL_ 792 EAC_CompElecPwrV 0 "Valid" 1 "Invalid";
VAL_ 792 EAC_CompSpdIncrReq 0 "False" 1 "True";
VAL_ 792 EAC_CompSpdV 0 "Valid" 1 "Invalid";
VAL_ 792 EAC_CompElecPwr 255 "Invaild";
VAL_ 792 EAC_CompSpd 16383 "Invaild";
VAL_ 792 EAC_CompElecCurr 255 "Invaild";
VAL_ 792 EAC_CompFltStat 0 "No Fault" 1 "Under Voltage" 2 "Over Voltage" 3 "Over Temperature" 4 "Input Control" 5 "Current Fault" 6 "Internal Fault" 8 "Motor slip protection" 9 "HVDC input voltage drop protection" 10 "Inside the controller 15V control power supply output undervoltage protection" 11 "Overcurrent frequency limitation and frequency reduction" 15 "Invalid";
VAL_ 937 VCU_PTC_RelaySts 1 "close" 0 "open";
VAL_ 937 VCU_EACEnbReq 1 "Enable" 0 "Disable";
VAL_ 937 VCU_EACAllowedPower 1023 "Invalid";
VAL_ 937 VCU_EAC_CompSpdReq 16383 "Invaild";
VAL_ 425 VCU_RegenLevel_Feed 3 "invalid" 2 "High" 1 "Low" 0 "none";
VAL_ 425 VCU_RBCSts 1 "active" 0 "incative";
VAL_ 425 VCU_RDCSts 1 "active" 0 "incative";
VAL_ 425 VCU_Veh_ERR 1 "Error" 0 "Normal";
VAL_ 425 VCU_DrvSys_ERR 1 "Error" 0 "Normal";
VAL_ 425 VCU_PackSys_ERR 1 "Error" 0 "Normal";
VAL_ 425 VCU_TBOX_Veh_STS_Reserved 3 "Other" 2 "Off" 1 "Start" 0 "Invalid";
VAL_ 425 VCU_VehChg_STS 3 "Charge fault" 2 "Charging complete" 1 "Charging in progress" 0 "Charging not in progress";
VAL_ 425 VCU_BatterVoltage_Reserved 255 "Invalid";
VAL_ 425 VCU_BatteryVoltErr_Reserved 1 "warning" 0 "no warning";
VAL_ 425 VCU_MotorCoolingCircuitErr_Reserved 1 "Error" 0 "Normal";
VAL_ 425 VCU_PackCoolingCircuitErr_Reserved 1 "Error" 0 "Normal";
VAL_ 425 VCU_VehicleHVStatus 3 "Reserved" 2 "ReadyToDrive" 1 "HV On" 0 "Not ready";
VAL_ 425 VCU_InstantPowerConsump 1023 "Invalid";
VAL_ 425 VCU_AveragePowerConsump 1023 "Invalid";
VAL_ 425 VCU_BrakePedalSts 3 "Invalid" 2 "Reserved" 1 "pressed" 0 "Not pressed";
VAL_ 1008 VCU_IMMO_Sts 2 "failed " 1 "pass " 0 "init";
VAL_ 1008 VCU_DCDCAllowedPower 511 "Invalid";
VAL_ 1008 VCU_Shift_ERR 1 "Error" 0 "Normal";
VAL_ 1008 VCU_VehicleDischargePower 127 "Invalid";
VAL_ 1008 VCU_VehicleChargePower 127 "Invalid";
VAL_ 533 Rolling_Counter_0x215 15 "Invalid";
VAL_ 533 BMS_SOE 255 "Invalid";
VAL_ 533 BMS_HWCrash_Sts 1 "Crash " 0 "No Crash";
VAL_ 533 BMS_HVIL_STS 2 "short to ground" 1 "Open & short to battery" 0 "Closed";
VAL_ 533 BMS_IGN_Sts 1 "ON " 0 "OFF";
VAL_ 533 BMS_Sys_STS 8 "Invalid" 7 "Failure, unable to operate" 6 "BCU Sleep mode" 5 "Successful Power Down" 4 "Power Down process" 3 "Successful Power Down of HV" 2 "Successful High Voltage Power Up" 1 "Self-check passes, can be high-voltage" 0 "Initialization of power on, self-checking";
VAL_ 533 BMS_HVOnOff_STS 3 "Fail to HV on " 2 "HV On " 1 "Precharge " 0 "HV Off";
VAL_ 533 BMS_Balance_STS 1 "active " 0 "Inactive";
VAL_ 533 BMS_SocActual_EST 1023 "Invalid";
VAL_ 533 BMS_BatBalance_ERR 1 "normal " 0 "Error";
VAL_ 533 BMS_ISU_Status 3 "Level3(<100 Ohms/V)" 2 "Level2(<200 Ohms/V)" 1 "Level1 <500 Ohms/V ~ >200 Ohms/V" 0 "Normal (> 500 Ohms/V)";
VAL_ 533 BMS_ERR_LEV 7 "Battery locked -Reserved" 6 "Fault, needs Shutdown and Wakeup" 5 "Emergency off condition" 4 "Delayed power down with FTTI" 3 "Power down without FTTI" 2 "Limp Home" 1 " Warning (any warning in system)" 0 "No error";
VAL_ 533 BMS_SOH 255 "Invalid";
VAL_ 533 BMS_HV_Sts 4 "AC Charge" 3 "Super Fast Charge" 2 "HV ON" 1 "Precharge" 0 "HV Off";
